VERSION ""

NS_ :

BS_:

BU_: _05_TCU _0B_GPS _0A_Precharge _00_CCU _01_MCU _02_Node_Pedal _03_Node_Front _04_HV_AMS _0B_Dash _06_LV_AMS _07_Shunt _08_Gyro _09_ASU _0C_VSU _0D_TSU_F _0E_TSU_R _0F_Node_Dflt Datalogger
VAL_TABLE_ VtAero_Range 3 "600-1100mBar" 2 "Differential" 1 "600-1200mBar" 0 "200-1200mBar" ;
VAL_TABLE_ VTable_ConfigIDs_CCU 15 "Voltage pump right" 14 "Voltage pump left" 13 "Laptrigger enabled (reboot)" 12 "Control eFuse Inverter right" 11 "Control eFuse Inverter left" 10 "Control eFuse Accumulator" 9 "Control eFuse CAN node" 8 "Torque pedal max way (mech lim)" 7 "Torque pedal full way (kickdown)" 6 "DRS mode" 5 "Fan Cooling manual speed" 4 "Fan Accu manual speed" 3 "Pump Inverter manual speed" 2 "Pump Motor manual speed" 1 "Cool mode" 0 "Reset Flash" ;
VAL_TABLE_ VTable_LV_AMS_I2C_State_Machine 4 "ShutdownPending" 3 "ManualRunning" 2 "ManualInit" 1 "Running" 0 "Init" ;
VAL_TABLE_ VTable_IMD_Status 2 "Undefined" 1 "Error" 0 "OK" ;
VAL_TABLE_ VTable_State_Bat 2 "State_Recalibrate" 1 "State_Load_Applied" 0 "State_Bat_Relaxed" ;
VAL_TABLE_ VTable_SOH_Estimator 3 "State_Reset" 2 "State_Running" 1 "State_Wait_For_Run" 0 "State_Init" ;
VAL_TABLE_ VTable_OCV_Estimator_State 3 "State_Reset" 2 "State_Running" 1 "State_Wait_For_Run" 0 "State_Init" ;
VAL_TABLE_ VTable_Bal_State 3 "State_Finished" 2 "State_Cool_Down" 1 "State_Active" 0 "State_Init" ;
VAL_TABLE_ DL_Status 8 "Error" 7 "Logging EM & FSD data" 5 "Logging FSD data" 3 "Logging EM data" 1 "DL idle, ready to log" ;

BO_ 3221225472 VECTOR__INDEPENDENT_SIG_MSG: 0 Vector__XXX
 SG_ New_Signal_471 : 0|8@1+ (1,0) [0|0] "" Vector__XXX
 SG_ New_Signal_470 : 0|8@1+ (1,0) [0|0] "" Vector__XXX
 SG_ Precharge_PM_Current_Too_High : 0|1@1+ (1,0) [0|1] "" Vector__XXX
 SG_ Current : 0|16@1- (0.05,0) [-1638.4|1638.35] "A" Vector__XXX
 SG_ Voltage : 0|16@1- (0.04,0) [-1310.72|1310.68] "V" Vector__XXX
 SG_ Power : 0|16@1- (3,0) [-98304|98301] "W" Vector__XXX
 SG_ Status : 0|8@1+ (1,0) [0|255] "" Vector__XXX
 SG_ MsgCntr : 0|8@1+ (1,0) [0|255] "" Vector__XXX
 SG_ NodeF_Force_FR : 0|16@0+ (0.02442,-28.8095) [0|100] "" Vector__XXX
 SG_ NodeR_Brake_Pressure : 0|16@0+ (0.03157,-12.9) [0|0] "Bar" Vector__XXX

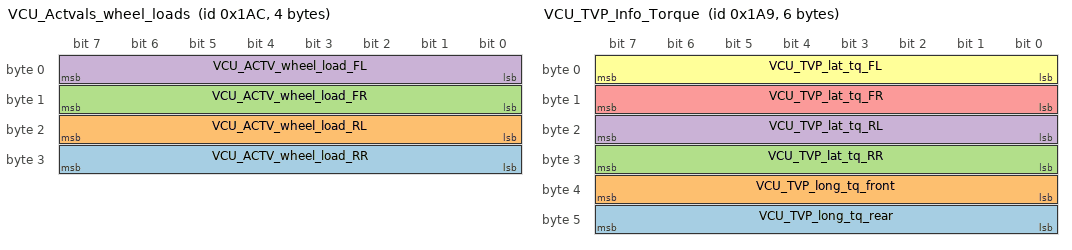
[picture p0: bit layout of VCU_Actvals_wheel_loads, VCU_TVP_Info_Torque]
BO_ 428 VCU_Actvals_wheel_loads: 4 Vector__XXX
 SG_ VCU_ACTV_wheel_load_RR : 24|8@1+ (10,0) [0|2550] "N" Vector__XXX
 SG_ VCU_ACTV_wheel_load_RL : 16|8@1+ (10,0) [0|2550] "N" Vector__XXX
 SG_ VCU_ACTV_wheel_load_FR : 8|8@1+ (10,0) [0|2550] "N" Vector__XXX
 SG_ VCU_ACTV_wheel_load_FL : 0|8@1+ (10,0) [0|2550] "N" Vector__XXX

BO_ 427 VCU_Actvals_steering: 6 Vector__XXX
 SG_ VCU_ACTV_wheel_angle_middle_deg : 32|16@1- (0.01,0) [-327.68|327.67] "deg" Vector__XXX
 SG_ VCU_ACTV_wheel_angle_FR : 16|16@1- (0.01,0) [-327.68|327.67] "deg" Vector__XXX
 SG_ VCU_ACTV_wheel_angle_FL : 0|16@1- (0.01,0) [-327.68|327.67] "deg" Vector__XXX

BO_ 425 VCU_TVP_Info_Torque: 6 Vector__XXX
 SG_ VCU_TVP_long_tq_rear : 40|8@1- (1,0) [-128|127] "%" Vector__XXX
 SG_ VCU_TVP_long_tq_front : 32|8@1- (1,0) [-128|127] "%" Vector__XXX
 SG_ VCU_TVP_lat_tq_RR : 24|8@1- (1,0) [-128|127] "%" Vector__XXX
 SG_ VCU_TVP_lat_tq_RL : 16|8@1- (1,0) [-128|127] "%" Vector__XXX
 SG_ VCU_TVP_lat_tq_FR : 8|8@1- (1,0) [-128|127] "%" Vector__XXX
 SG_ VCU_TVP_lat_tq_FL : 0|8@1- (1,0) [-128|127] "%" Vector__XXX

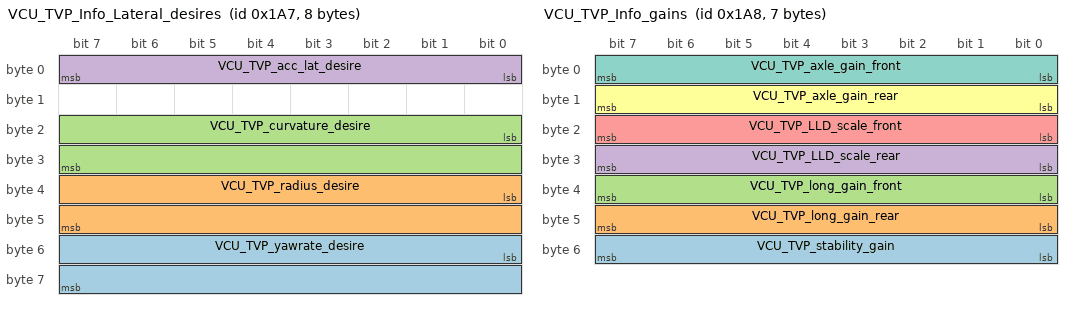
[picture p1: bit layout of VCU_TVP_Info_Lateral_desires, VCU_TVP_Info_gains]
BO_ 423 VCU_TVP_Info_Lateral_desires: 8 Vector__XXX
 SG_ VCU_TVP_yawrate_desire : 48|16@1- (0.001,0) [-32.768|32.767] "rad/s" Vector__XXX
 SG_ VCU_TVP_radius_desire : 32|16@1+ (0.1,0) [0|6553.5] "m" Vector__XXX
 SG_ VCU_TVP_curvature_desire : 16|16@1- (0.0001,0) [-3.2768|3.2767] "1/m" Vector__XXX
 SG_ VCU_TVP_acc_lat_desire : 0|8@1+ (0.1,0) [0|25.5] "m/s/s" Vector__XXX

BO_ 424 VCU_TVP_Info_gains: 7 Vector__XXX
 SG_ VCU_TVP_stability_gain : 48|8@1- (1,0) [-128|127] "%" Vector__XXX
 SG_ VCU_TVP_long_gain_rear : 40|8@1+ (1,0) [0|255] "%" Vector__XXX
 SG_ VCU_TVP_long_gain_front : 32|8@1+ (1,0) [0|255] "%" Vector__XXX
 SG_ VCU_TVP_LLD_scale_rear : 24|8@1+ (1,0) [0|255] "%" Vector__XXX
 SG_ VCU_TVP_LLD_scale_front : 16|8@1+ (1,0) [0|255] "%" Vector__XXX
 SG_ VCU_TVP_axle_gain_rear : 8|8@1- (1,0) [-128|127] "%" Vector__XXX
 SG_ VCU_TVP_axle_gain_front : 0|8@1- (1,0) [-128|127] "%" Vector__XXX

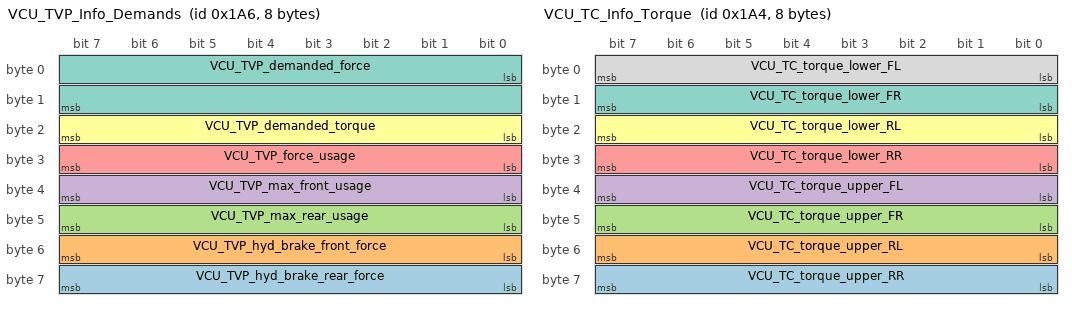
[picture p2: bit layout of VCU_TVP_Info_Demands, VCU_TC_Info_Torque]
BO_ 422 VCU_TVP_Info_Demands: 8 Vector__XXX
 SG_ VCU_TVP_hyd_brake_rear_force : 56|8@1+ (-10,0) [-2550|0] "N" Vector__XXX
 SG_ VCU_TVP_hyd_brake_front_force : 48|8@1+ (-10,0) [-2550|0] "N" Vector__XXX
 SG_ VCU_TVP_max_rear_usage : 40|8@1+ (1,0) [0|255] "%" Vector__XXX
 SG_ VCU_TVP_max_front_usage : 32|8@1+ (1,0) [0|255] "%" Vector__XXX
 SG_ VCU_TVP_force_usage : 24|8@1- (1,0) [-128|127] "%" Vector__XXX
 SG_ VCU_TVP_demanded_torque : 16|8@1- (1,0) [-128|127] "%" Vector__XXX
 SG_ VCU_TVP_demanded_force : 0|16@1- (1,0) [-32768|32767] "N" Vector__XXX

BO_ 421 VCU_TC_Info_Speed: 8 Vector__XXX
 SG_ VCU_TC_upper_speed_RR : 48|16@1+ (0.1,0) [0|6553.5] "rad/s" Vector__XXX
 SG_ VCU_TC_upper_speed_RL : 32|16@1+ (0.1,0) [0|6553.5] "rad/s" Vector__XXX
 SG_ VCU_TC_upper_speed_FR : 16|16@1+ (0.1,0) [0|6553.5] "rad/s" Vector__XXX
 SG_ VCU_TC_upper_speed_FL : 0|16@1+ (0.1,0) [0|6553.5] "rad/s" Vector__XXX

BO_ 420 VCU_TC_Info_Torque: 8 Vector__XXX
 SG_ VCU_TC_torque_upper_RR : 56|8@1- (1,0) [-128|127] "%" Vector__XXX
 SG_ VCU_TC_torque_upper_RL : 48|8@1- (1,0) [-128|127] "%" Vector__XXX
 SG_ VCU_TC_torque_upper_FR : 40|8@1- (1,0) [-128|127] "%" Vector__XXX
 SG_ VCU_TC_torque_upper_FL : 32|8@1- (1,0) [-128|127] "%" Vector__XXX
 SG_ VCU_TC_torque_lower_RR : 24|8@1- (1,0) [-128|127] "%" Vector__XXX
 SG_ VCU_TC_torque_lower_RL : 16|8@1- (1,0) [-128|127] "%" Vector__XXX
 SG_ VCU_TC_torque_lower_FR : 8|8@1- (1,0) [-128|127] "%" Vector__XXX
 SG_ VCU_TC_torque_lower_FL : 0|8@1- (1,0) [-128|127] "%" Vector__XXX

BO_ 419 VCU_PL_Limits: 2 Vector__XXX
 SG_ VCU_PL_Tq_max_lim : 8|8@1+ (1,0) [0|255] "%" Vector__XXX
 SG_ VCU_PL_Tq_min_lim : 0|8@1+ (-1,0) [-255|0] "%" Vector__XXX

BO_ 417 VCU_CFG_SETPOINTS_2: 8 Vector__XXX

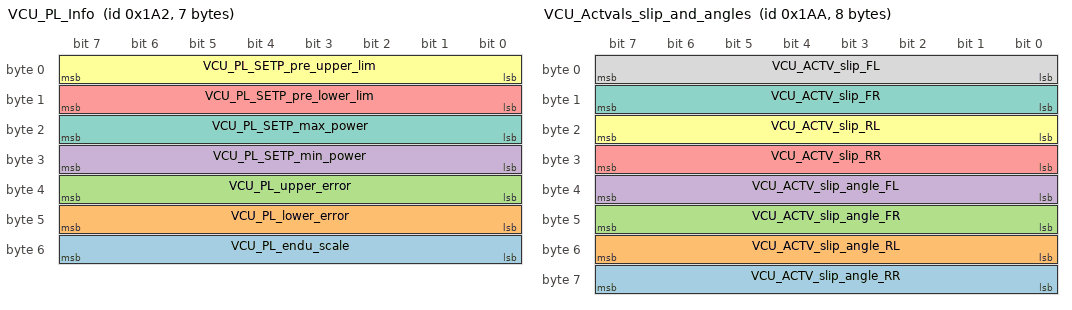
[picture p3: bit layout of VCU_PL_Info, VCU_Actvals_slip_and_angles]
BO_ 418 VCU_PL_Info: 7 Vector__XXX
 SG_ VCU_PL_endu_scale : 48|8@1+ (0.01,0) [0|2.55] "" Vector__XXX
 SG_ VCU_PL_lower_error : 40|8@1- (0.01,0) [-1.28|1.27] "" Vector__XXX
 SG_ VCU_PL_upper_error : 32|8@1- (0.01,0) [-1.28|1.27] "" Vector__XXX
 SG_ VCU_PL_SETP_min_power : 24|8@1- (1,0) [-128|127] "kW" Vector__XXX
 SG_ VCU_PL_SETP_pre_lower_lim : 8|8@1+ (-0.01,0) [-2.55|0] "" Vector__XXX
 SG_ VCU_PL_SETP_pre_upper_lim : 0|8@1- (0.01,0) [0|2.55] "" Vector__XXX
 SG_ VCU_PL_SETP_max_power : 16|8@1- (1,0) [-128|127] "kW" Vector__XXX

BO_ 426 VCU_Actvals_slip_and_angles: 8 Vector__XXX
 SG_ VCU_ACTV_slip_angle_RR : 56|8@1- (0.2,0) [-25.6|25.4] "deg" Vector__XXX
 SG_ VCU_ACTV_slip_angle_RL : 48|8@1- (0.2,0) [-25.6|25.4] "deg" Vector__XXX
 SG_ VCU_ACTV_slip_angle_FR : 40|8@1- (0.2,0) [-25.6|25.4] "deg" Vector__XXX
 SG_ VCU_ACTV_slip_angle_FL : 32|8@1- (0.2,0) [-25.6|25.4] "deg" Vector__XXX
 SG_ VCU_ACTV_slip_RR : 24|8@1- (1,0) [-128|127] "%" Vector__XXX
 SG_ VCU_ACTV_slip_RL : 16|8@1- (1,0) [-128|127] "%" Vector__XXX
 SG_ VCU_ACTV_slip_FR : 8|8@1- (1,0) [-128|127] "%" Vector__XXX
 SG_ VCU_ACTV_slip_FL : 0|8@1- (1,0) [-128|127] "%" Vector__XXX

BO_ 277 VCU_ACTVALS_1: 3 Vector__XXX
 SG_ VCU_ACTV_DRIVER_PEDALS : 16|8@1- (1,0) [-128|127] "%" Vector__XXX
 SG_ VCU_ACT_TS_POWER : 0|16@1- (0.01,0) [-327.68|327.67] "kW" Vector__XXX

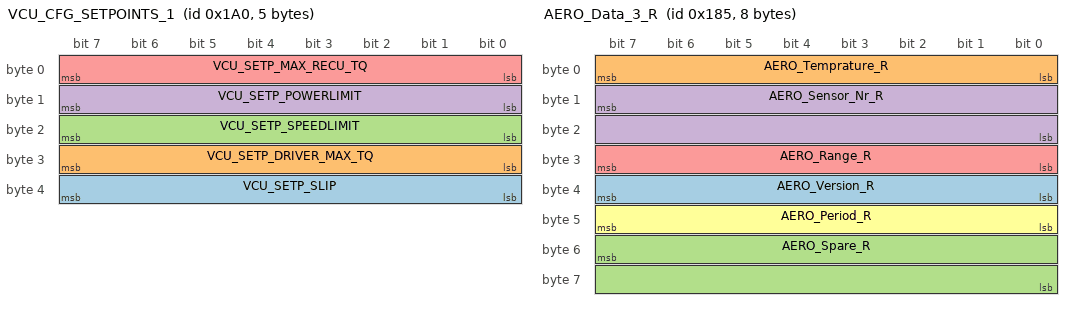
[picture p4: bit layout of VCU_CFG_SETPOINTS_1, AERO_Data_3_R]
BO_ 416 VCU_CFG_SETPOINTS_1: 5 Vector__XXX
 SG_ VCU_SETP_SLIP : 32|8@1+ (1,0) [0|255] "%" Vector__XXX
 SG_ VCU_SETP_DRIVER_MAX_TQ : 24|8@1+ (1,0) [0|100] "%" Vector__XXX
 SG_ VCU_SETP_SPEEDLIMIT : 16|8@1+ (1,0) [0|255] "km/h" Vector__XXX
 SG_ VCU_SETP_POWERLIMIT : 8|8@1+ (1,0) [0|255] "kW" Vector__XXX
 SG_ VCU_SETP_MAX_RECU_TQ : 0|8@1+ (0.1,0) [0|25.5] "Nm" Vector__XXX

BO_ 1008 TSU_N_FR: 8 _0D_TSU_F
 SG_ TSU_NT_C6 : 55|16@0+ (0.1,0) [-20|200] "°C" Vector__XXX
 SG_ TSU_NT_C5 : 39|16@0+ (0.1,0) [-20|200] "°C" Vector__XXX
 SG_ TSU_NT_C4 : 23|16@0+ (0.1,0) [-20|200] "°C" Vector__XXX
 SG_ TSU_NT_C3 : 7|16@0+ (0.1,0) [-20|200] "°C" Vector__XXX

BO_ 392 NodeF_SensorData_2: 8 Vector__XXX
 SG_ NodeF_Spring_Heave : 7|16@0+ (0.024652,-15.6787) [0|100] "mm" Vector__XXX
 SG_ NodeF_Force_FL : 23|16@0+ (0.02442,-28.8095) [0|100] "" Vector__XXX

BO_ 391 NodeR_Force: 4 Vector__XXX
 SG_ NodeR_Force_FR : 23|16@0+ (0.02442,-28.8095) [0|100] "" Vector__XXX
 SG_ NodeR_Force_FL : 7|16@0+ (0.02442,-28.8095) [0|100] "" Vector__XXX

BO_ 390 NodeR_SensorData: 8 Vector__XXX
 SG_ NodeR_Spring_Heave : 39|16@0+ (0.030758,-67.6368) [0|100] "mm" Vector__XXX
 SG_ NodeR_Spring_RL : 7|16@0+ (0.018423,-28.3641) [0|100] "mm" Vector__XXX
 SG_ NodeR_Spring_RR : 23|16@0+ (0.018464,-30.4627) [0|100] "mm" Vector__XXX

BO_ 389 AERO_Data_3_R: 8 Vector__XXX
 SG_ AERO_Version_R : 39|8@0+ (1,0) [0|0] "" Vector__XXX
 SG_ AERO_Temprature_R : 7|8@0- (1,0) [-10|100] "C" Vector__XXX
 SG_ AERO_Spare_R : 55|16@0+ (1,0) [0|0] "" Vector__XXX
 SG_ AERO_Sensor_Nr_R : 15|16@0+ (1,0) [0|0] "" Vector__XXX
 SG_ AERO_Range_R : 31|8@0+ (1,0) [0|0] "" Vector__XXX
 SG_ AERO_Period_R : 47|8@0+ (1,0) [0|0] "ms" Vector__XXX

BO_ 388 AERO_Data_2_R: 8 Vector__XXX
 SG_ AERO_Pressure8_R : 55|16@0+ (0.01,600) [600|1200] "mBar" Vector__XXX
 SG_ AERO_Pressure7_R : 39|16@0+ (0.01,600) [600|1200] "mBar" Vector__XXX
 SG_ AERO_Pressure6_R : 23|16@0+ (0.01,600) [600|1200] "mBar" Vector__XXX
 SG_ AERO_Pressure5_R : 7|16@0+ (0.01,600) [600|1200] "mBar" Vector__XXX

BO_ 387 AERO_Data_1_R: 8 Vector__XXX
 SG_ AERO_Pressure4_R : 55|16@0+ (0.01,600) [600|1200] "mBar" Vector__XXX
 SG_ AERO_Pressure3_R : 39|16@0+ (0.01,600) [600|1200] "mBar" Vector__XXX
 SG_ AERO_Pressure2_R : 23|16@0+ (0.01,600) [600|1200] "mBar" Vector__XXX
 SG_ AERO_Pressure1_R : 7|16@0+ (0.01,600) [600|1200] "mBar" Vector__XXX

BO_ 2035 AERO_Config_3: 8 Vector__XXX
 SG_ AERO_Opcode_3 : 7|8@0+ (1,0) [0|0] "" Vector__XXX
 SG_ AERO_MultiConfig_3 : 23|48@0+ (1,0) [0|0] "" Vector__XXX
 SG_ AERO_Message_Type_3 : 15|8@0+ (1,0) [0|0] "" Vector__XXX

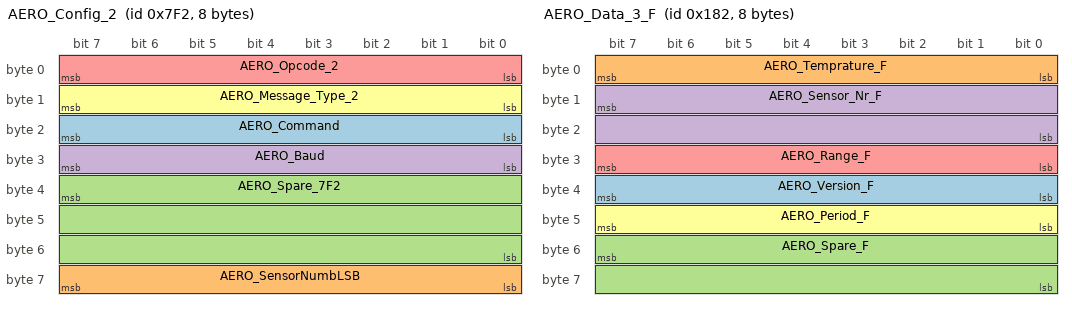
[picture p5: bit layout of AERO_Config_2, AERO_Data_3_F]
BO_ 2034 AERO_Config_2: 8 Vector__XXX
 SG_ AERO_Command : 23|8@0+ (1,0) [0|0] "" Vector__XXX
 SG_ AERO_SensorNumbLSB : 56|8@1- (1,0) [0|0] "" Vector__XXX
 SG_ AERO_Spare_7F2 : 39|24@0+ (1,0) [0|0] "" Vector__XXX
 SG_ AERO_Baud : 31|8@0+ (1,0) [0|0] "" Vector__XXX
 SG_ AERO_Opcode_2 : 7|8@0+ (1,0) [0|0] "" Vector__XXX
 SG_ AERO_Message_Type_2 : 15|8@0+ (1,0) [0|0] "" Vector__XXX

BO_ 2033 AERO_Config_1: 8 Vector__XXX
 SG_ AERO_MultiConfig_1 : 23|48@0+ (1,0) [0|0] "" Vector__XXX
 SG_ AERO_Message_Type_1 : 15|8@0+ (1,0) [0|0] "" Vector__XXX
 SG_ AERO_Opcode_1 : 7|8@0+ (1,0) [0|0] "" Vector__XXX

BO_ 386 AERO_Data_3_F: 8 Vector__XXX
 SG_ AERO_Version_F : 39|8@0+ (1,0) [0|0] "" Vector__XXX
 SG_ AERO_Temprature_F : 7|8@0- (1,0) [-10|100] "C" Vector__XXX
 SG_ AERO_Spare_F : 55|16@0+ (1,0) [0|0] "" Vector__XXX
 SG_ AERO_Sensor_Nr_F : 15|16@0+ (1,0) [0|0] "" Vector__XXX
 SG_ AERO_Range_F : 31|8@0+ (1,0) [0|0] "" Vector__XXX
 SG_ AERO_Period_F : 47|8@0+ (1,0) [0|0] "ms" Vector__XXX

BO_ 385 AERO_Data_2_F: 8 Vector__XXX
 SG_ AERO_Pressure8_F : 55|16@0+ (0.01,600) [600|1200] "mBar" Vector__XXX
 SG_ AERO_Pressure7_F : 39|16@0+ (0.01,600) [600|1200] "mBar" Vector__XXX
 SG_ AERO_Pressure6_F : 23|16@0+ (0.01,600) [600|1200] "mBar" Vector__XXX
 SG_ AERO_Pressure5_F : 7|16@0+ (0.01,600) [600|1200] "mBar" Vector__XXX

BO_ 384 AERO_Data_1_F: 8 Vector__XXX
 SG_ AERO_Pressure4_F : 55|16@0+ (0.01,600) [600|1200] "mBar" Vector__XXX
 SG_ AERO_Pressure3_F : 39|16@0+ (0.01,600) [600|1200] "mBar" Vector__XXX
 SG_ AERO_Pressure2_F : 23|16@0+ (0.01,600) [600|1200] "mBar" Vector__XXX
 SG_ AERO_Pressure1_F : 7|16@0+ (0.01,600) [600|1200] "mBar" Vector__XXX

BO_ 1973 Config_Tel_Write_Dash: 4 _05_TCU
 SG_ Dash_Config_Value_W : 23|16@0+ (1,0) [0|0] "" Vector__XXX
 SG_ Dash_Config_ID_W : 7|16@0+ (1,0) [0|0] "" Vector__XXX

BO_ 1717 Config_Tel_Read_Dash: 4 _05_TCU
 SG_ Dash_Config_Value_RD : 23|16@0+ (1,0) [0|0] "" Vector__XXX
 SG_ Dash_Config_ID_RD : 7|16@0+ (1,0) [0|0] "" Vector__XXX

BO_ 1627 Config_Tel_Response_Dash: 4 _0B_Dash
 SG_ Dash_Config_Value_RX : 23|16@0+ (1,0) [0|0] "" Vector__XXX
 SG_ Dash_Config_ID_RX : 7|16@0+ (1,0) [0|0] "" Vector__XXX

BO_ 773 TCU_Monitoring: 2 _05_TCU
 SG_ TCU_Current_consumption : 7|16@0+ (0.00013573,0) [0|0.56] "A" Vector__XXX

BO_ 292 AMS_Capacity_And_OCV: 4 Vector__XXX
 SG_ AMS_OCV : 23|16@0- (1,0) [2700|4200] "mV" Vector__XXX
 SG_ AMS_Capacity : 7|16@0- (0.001,0) [0|0] "Ah" Vector__XXX

BO_ 976 CCU_LV_Currents_3_RS17: 2 _00_CCU
 SG_ CCU_Current_LV_Fans_Cooling_RS17 : 7|16@0+ (0.006104432,0) [0|25] "A" Vector__XXX

BO_ 529 MCU_Act_Vals_3: 3 _01_MCU
 SG_ MCU_ActVal_Speed_Filtered : 15|16@0- (0.1,0) [0|0] "m/s" Vector__XXX
 SG_ MCU_ActVal_Max_Recup_Curr_Setp : 7|8@0+ (1,0) [0|255] "A" Vector__XXX

BO_ 1021 GPS_Status: 8 _0B_GPS
 SG_ MsgAnzahl m1 : 56|8@1+ (1,0) [0|12] "" Vector__XXX
 SG_ MsgNummer m1 : 48|8@1+ (1,0) [0|12] "" Vector__XXX
 SG_ SNR m1 : 40|8@1+ (1,0) [0|99] "dBhz" Vector__XXX
 SG_ Erhebungswinkel m1 : 32|8@1- (1,0) [-9|90] "Grad" Vector__XXX
 SG_ Azimut m1 : 16|16@1+ (1,0) [0|359] "Grad" Vector__XXX
 SG_ Sat_ID m1 : 8|8@1+ (1,0) [1|32] "" Vector__XXX
 SG_ Sat_aktiv m1 : 0|4@1+ (1,0) [0|1] "" Vector__XXX
 SG_ VDOP m0 : 48|16@1+ (0.1,0) [0|99.9] "m" Vector__XXX
 SG_ HDOP m0 : 32|16@1+ (0.1,0) [0|99.9] "m" Vector__XXX
 SG_ PDOP m0 : 16|16@1+ (0.1,0) [0|99.9] "m" Vector__XXX
 SG_ AnzSichtbSat m0 : 8|8@1+ (1,0) [0|12] "" Vector__XXX
 SG_ AnzAktSat m0 : 0|4@1+ (1,0) [0|12] "" Vector__XXX
 SG_ Typ M : 4|4@1+ (1,0) [0|1] "" Vector__XXX

BO_ 1020 GPS_Speed: 4 _0B_GPS
 SG_ GPS_course : 16|16@1+ (0.1,0) [0|359.9] "Grad" Vector__XXX
 SG_ GPS_speed : 0|16@1+ (0.1,0) [0|999.9] "km/h" Vector__XXX

BO_ 1019 GPS_Location: 8 _0B_GPS
 SG_ GPS_x : 32|32@1- (2.7777777778E-006,0) [-180|180] "Grad" Vector__XXX
 SG_ GPS_y : 0|32@1- (2.7777777778E-006,0) [-90|90] "Grad" Vector__XXX

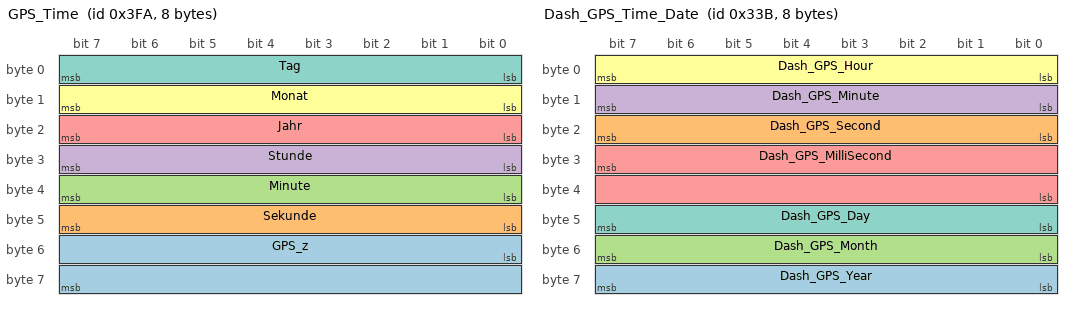
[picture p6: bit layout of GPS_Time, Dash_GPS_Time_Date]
BO_ 1018 GPS_Time: 8 _0B_GPS
 SG_ GPS_z : 48|16@1- (1,0) [-9999|32767] "m" Vector__XXX
 SG_ Sekunde : 40|8@1+ (1,0) [0|59] "Sekunden" Vector__XXX
 SG_ Minute : 32|8@1+ (1,0) [0|59] "Minuten" Vector__XXX
 SG_ Stunde : 24|8@1+ (1,0) [0|23] "Stunden" Vector__XXX
 SG_ Jahr : 16|8@1+ (1,0) [0|99] "Jahr" Vector__XXX
 SG_ Monat : 8|8@1+ (1,0) [1|12] "Monat" Vector__XXX
 SG_ Tag : 0|8@1+ (1,0) [1|31] "Tag" Vector__XXX

BO_ 282 Precharge_Monitoring: 8 _0A_Precharge
 SG_ Precharge_PreRel_closed : 31|1@1+ (1,0) [0|0] "" Vector__XXX
 SG_ Precharge_AIR2_closed : 30|1@1+ (1,0) [0|0] "" Vector__XXX
 SG_ Precharge_AIR1_closed : 29|1@1+ (1,0) [0|0] "" Vector__XXX
 SG_ Precharge_Time_Min : 39|16@0+ (1,0) [0|0] "ms" Vector__XXX
 SG_ Precharge_Time_Max : 55|16@0+ (1,0) [0|0] "ms" Vector__XXX
 SG_ Precharge_uC_Reset : 27|1@1+ (1,0) [0|1] "" Vector__XXX
 SG_ Precharge_uC_OK : 28|1@1+ (1,0) [0|1] "" Vector__XXX
 SG_ Precharge_Current : 7|16@0- (1,0) [-32768|32767] "A" Vector__XXX
 SG_ Precharge_PM_Pre_Sig : 18|1@1+ (1,0) [0|1] "" Vector__XXX
 SG_ Precharge_PM_Pre_Run_Min_Latch : 25|1@1+ (1,0) [0|1] "" Vector__XXX
 SG_ Precharge_PM_Pre_Run : 24|1@1+ (1,0) [0|1] "" Vector__XXX
 SG_ Precharge_PM_Pre_Reset_Inv : 22|1@1+ (1,0) [0|1] "" Vector__XXX
 SG_ Precharge_PM_Pre_Less_40V : 26|1@1+ (1,0) [0|1] "" Vector__XXX
 SG_ Precharge_PM_Pre_AUX : 21|1@1+ (1,0) [0|1] "" Vector__XXX
 SG_ Precharge_PM_AIR2_Sig : 17|1@1+ (1,0) [0|1] "" Vector__XXX
 SG_ Precharge_PM_AIR2_AUX : 20|1@1+ (1,0) [0|1] "" Vector__XXX
 SG_ Precharge_PM_AIR1_Sig : 16|1@1+ (1,0) [0|1] "" Vector__XXX
 SG_ Precharge_PM_AIR1_AUX : 19|1@1+ (1,0) [0|1] "" Vector__XXX
 SG_ Precharge_PM_5V_SC : 23|1@1+ (1,0) [0|1] "" Vector__XXX

BO_ 944 CCU_Cooling_Temps: 8 _00_CCU
 SG_ CCU_Temp_MotR_Out_MotF_In : 55|16@0+ (0.0225,-10) [0|0] "deg" Vector__XXX
 SG_ CCU_Temp_Inv_Out_Mot_In : 39|16@0+ (0.0225,-10) [0|0] "deg" Vector__XXX
 SG_ CCU_Temp_MotF_Out_HE_In : 23|16@0+ (0.0225,-10) [0|0] "deg" Vector__XXX
 SG_ CCU_Temp_HE_Out_Inv_In : 7|16@0+ (0.0225,-10) [0|0] "deg" Vector__XXX

BO_ 843 Dash_GPS_Status: 4 _0B_Dash
 SG_ Dash_GPS_Velocity : 23|16@0+ (1,0) [0|0] "" Vector__XXX
 SG_ Dash_GPS_Signal_Integrity : 15|8@0+ (1,0) [0|0] "" Vector__XXX
 SG_ Dash_GPS_Satelite : 7|8@0+ (1,0) [0|0] "" Vector__XXX

BO_ 827 Dash_GPS_Time_Date: 8 _0B_Dash
 SG_ Dash_GPS_Year : 63|8@0+ (1,0) [0|0] "" Vector__XXX
 SG_ Dash_GPS_Second : 23|8@0+ (1,0) [0|0] "" Vector__XXX
 SG_ Dash_GPS_Month : 55|8@0+ (1,0) [0|0] "" Vector__XXX
 SG_ Dash_GPS_Minute : 15|8@0+ (1,0) [0|0] "" Vector__XXX
 SG_ Dash_GPS_MilliSecond : 31|16@0+ (1,0) [0|0] "" Vector__XXX
 SG_ Dash_GPS_Hour : 7|8@0+ (1,0) [0|0] "" Vector__XXX
 SG_ Dash_GPS_Day : 47|8@0+ (1,0) [0|0] "" Vector__XXX

BO_ 811 Dash_GPS_Long_Lat: 8 _0B_Dash
 SG_ Dash_GPS_Longitude : 39|32@0+ (1,0) [0|0] "" Vector__XXX
 SG_ Dash_GPS_Latitude : 7|32@0+ (1,0) [0|0] "" Vector__XXX

BO_ 795 Dash_Lap_Time: 3 _0B_Dash
 SG_ Dash_Lap_Time : 7|24@0+ (0.001,0) [0|0] "" Vector__XXX

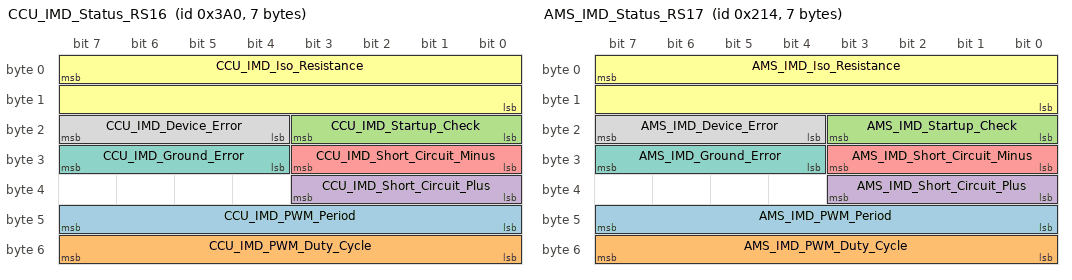
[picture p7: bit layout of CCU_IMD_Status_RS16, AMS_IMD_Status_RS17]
BO_ 928 CCU_IMD_Status_RS16: 7 _00_CCU
 SG_ CCU_IMD_PWM_Period : 47|8@0+ (1,0) [0|0] "Hz" Vector__XXX
 SG_ CCU_IMD_PWM_Duty_Cycle : 55|8@0+ (1,0) [0|0] "%" Vector__XXX
 SG_ CCU_IMD_Startup_Check : 16|4@1+ (1,0) [0|0] "" Vector__XXX
 SG_ CCU_IMD_Short_Circuit_Plus : 32|4@1+ (1,0) [0|0] "" Vector__XXX
 SG_ CCU_IMD_Short_Circuit_Minus : 24|4@1+ (1,0) [0|0] "" Vector__XXX
 SG_ CCU_IMD_Iso_Resistance : 7|16@0+ (0.001,0) [0|6] "MOhm" Vector__XXX
 SG_ CCU_IMD_Ground_Error : 28|4@1+ (1,0) [0|0] "" Vector__XXX
 SG_ CCU_IMD_Device_Error : 20|4@1+ (1,0) [0|0] "" Vector__XXX

BO_ 1110 LV_AMS_Internal_States: 2 _06_LV_AMS
 SG_ LV_AMS_Number_Of_Cells : 15|8@0+ (1,0) [3|8] "" Vector__XXX
 SG_ LV_AMS_I2C_State_Machine : 7|8@0+ (1,0) [0|0] "" Vector__XXX

BO_ 550 LV_AMS_Temps: 8 _06_LV_AMS
 SG_ LV_AMS_Temp_Internal : 55|16@0+ (0.1,0) [0|60] "C" Vector__XXX
 SG_ LV_AMS_Cell_Temp_Min : 39|16@0- (0.1,0) [0|60] "C" Vector__XXX
 SG_ LV_AMS_Cell_Temp_Max : 7|16@0- (0.1,0) [0|60] "C" Vector__XXX
 SG_ LV_AMS_Cell_Temp_Avg : 23|16@0- (0.1,0) [0|60] "C" Vector__XXX

BO_ 532 AMS_IMD_Status_RS17: 7 _04_HV_AMS
 SG_ AMS_IMD_PWM_Period : 47|8@0+ (1,0) [0|0] "Hz" Vector__XXX
 SG_ AMS_IMD_PWM_Duty_Cycle : 55|8@0+ (1,0) [0|0] "%" Vector__XXX
 SG_ AMS_IMD_Startup_Check : 16|4@1+ (1,0) [0|0] "" Vector__XXX
 SG_ AMS_IMD_Short_Circuit_Plus : 32|4@1+ (1,0) [0|0] "" Vector__XXX
 SG_ AMS_IMD_Short_Circuit_Minus : 24|4@1+ (1,0) [0|0] "" Vector__XXX
 SG_ AMS_IMD_Iso_Resistance : 7|16@0+ (0.001,0) [0|6] "MOhm" Vector__XXX
 SG_ AMS_IMD_Ground_Error : 28|4@1+ (1,0) [0|0] "" Vector__XXX
 SG_ AMS_IMD_Device_Error : 20|4@1+ (1,0) [0|0] "" Vector__XXX

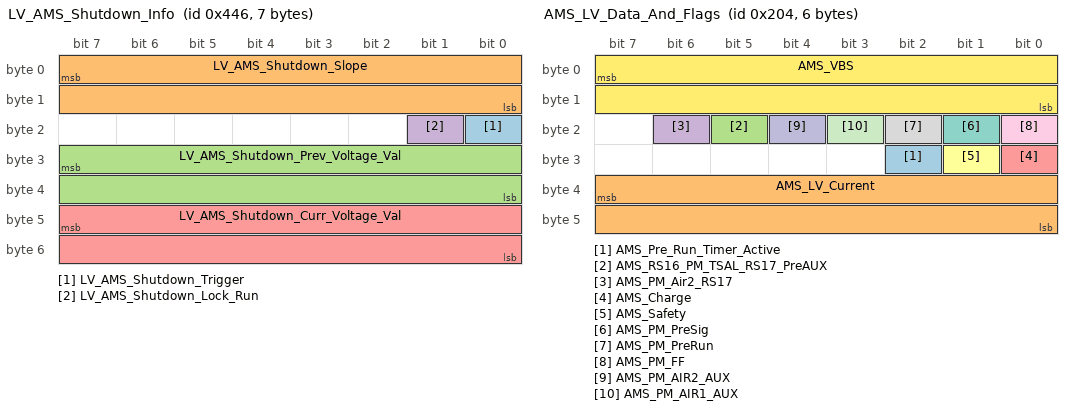
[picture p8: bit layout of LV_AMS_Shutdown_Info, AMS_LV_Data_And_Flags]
BO_ 1094 LV_AMS_Shutdown_Info: 7 _06_LV_AMS
 SG_ LV_AMS_Shutdown_Trigger : 16|1@0+ (1,0) [0|0] "" Vector__XXX
 SG_ LV_AMS_Shutdown_Slope : 7|16@0- (1,0) [0|0] "" Vector__XXX
 SG_ LV_AMS_Shutdown_Prev_Voltage_Val : 31|16@0+ (1,0) [0|0] "" Vector__XXX
 SG_ LV_AMS_Shutdown_Lock_Run : 17|1@0+ (1,0) [0|0] "" Vector__XXX
 SG_ LV_AMS_Shutdown_Curr_Voltage_Val : 47|16@0+ (1,0) [0|0] "" Vector__XXX

BO_ 1078 LV_AMS_Diagnostic_Data_3: 8 _06_LV_AMS
 SG_ LV_AMS_Temp_Cell_6 : 55|16@0+ (0.1,0) [0|60] "C" Vector__XXX
 SG_ LV_AMS_Temp_Cell_5 : 39|16@0+ (0.1,0) [0|60] "C" Vector__XXX
 SG_ LV_AMS_Temp_Cell_4 : 23|16@0+ (0.1,0) [0|60] "C" Vector__XXX
 SG_ LV_AMS_Temp_Cell_3 : 7|16@0+ (0.1,0) [0|60] "C" Vector__XXX

BO_ 779 Dash_Monitoring: 2 _0B_Dash
 SG_ Dash_Current_consumption : 7|16@0+ (0.00013573,0) [0|0.56] "A" Vector__XXX

BO_ 912 CCU_LV_Currents_2_RS17: 8 _00_CCU
 SG_ CCU_Current_LV_Inverter_R_RS17 : 55|16@0+ (0.001150741,0) [0|5] "A" Vector__XXX
 SG_ CCU_Current_LV_Inverter_L_RS17 : 39|16@0+ (0.001150741,0) [0|5] "A" Vector__XXX
 SG_ CCU_Current_LV_Optical_Sens_RS17 : 23|16@0+ (0.001150741,0) [0|5] "A" Vector__XXX
 SG_ CCU_Current_LV_Accu_RS17 : 7|16@0+ (0.001150741,0) [0|5] "A" Vector__XXX

BO_ 896 CCU_LV_Currents_1_RS17: 8 _00_CCU
 SG_ CCU_Current_LV_Fans_Accu_RS17 : 55|16@0+ (0.006104432,0) [0|25] "A" Vector__XXX
 SG_ CCU_Current_LV_Pumps_RS17 : 39|16@0+ (0.006104432,0) [0|25] "A" Vector__XXX
 SG_ CCU_Current_LV_CCU_RS17 : 23|16@0+ (0.000367258,0) [0|1.5] "A" Vector__XXX
 SG_ CCU_Current_LV_Total_RS17 : 7|16@0+ (0.006104432,0) [0|25] "A" Vector__XXX

BO_ 516 AMS_LV_Data_And_Flags: 6 _04_HV_AMS
 SG_ AMS_Pre_Run_Timer_Active : 26|1@1+ (1,0) [0|0] "" Vector__XXX
 SG_ AMS_LV_Current : 39|16@0+ (1,0) [0|0] "" Vector__XXX
 SG_ AMS_RS16_PM_TSAL_RS17_PreAUX : 21|1@0+ (1,0) [0|0] "" Vector__XXX
 SG_ AMS_PM_Air2_RS17 : 22|1@0+ (1,0) [0|0] "" Vector__XXX
 SG_ AMS_Charge : 24|1@0+ (1,0) [0|0] "" Vector__XXX
 SG_ AMS_Safety : 25|1@0+ (1,0) [0|0] "" Vector__XXX
 SG_ AMS_PM_PreSig : 17|1@0+ (1,0) [0|0] "" Vector__XXX
 SG_ AMS_PM_PreRun : 18|1@0+ (1,0) [0|0] "" Vector__XXX
 SG_ AMS_PM_FF : 16|1@0+ (1,0) [0|0] "" Vector__XXX
 SG_ AMS_PM_AIR2_AUX : 20|1@0+ (1,0) [0|0] "" Vector__XXX
 SG_ AMS_PM_AIR1_AUX : 19|1@0+ (1,0) [0|0] "" Vector__XXX
 SG_ AMS_VBS : 7|16@0+ (0.01055,0) [15|35] "V" Vector__XXX

BO_ 948 AMS_Fail_Counter_2: 3 _04_HV_AMS
 SG_ AMS_ISR_OOB_Failcounter : 23|8@0+ (1,0) [0|20] "" Vector__XXX
 SG_ AMS_Fail_Counter_COM_Recov : 15|8@0+ (1,0) [0|20] "" Vector__XXX
 SG_ AMS_Fail_Counter_Cell_Limit_Exc : 7|8@0+ (1,0) [0|0] "" Vector__XXX

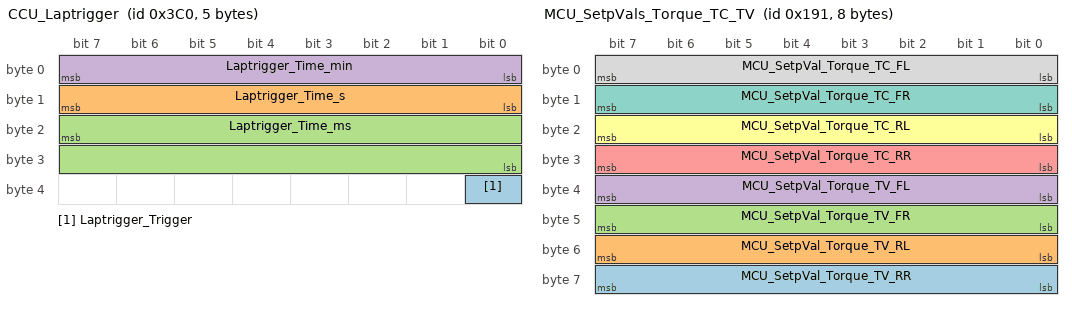
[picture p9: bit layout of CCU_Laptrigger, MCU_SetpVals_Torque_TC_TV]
BO_ 960 CCU_Laptrigger: 5 _00_CCU
 SG_ Laptrigger_Trigger : 32|1@0+ (1,0) [0|0] "" Vector__XXX
 SG_ Laptrigger_Time_s : 15|8@0+ (1,0) [0|0] "s" Vector__XXX
 SG_ Laptrigger_Time_ms : 23|16@0+ (1,0) [0|0] "ms" Vector__XXX
 SG_ Laptrigger_Time_min : 7|8@0+ (1,0) [0|0] "min" Vector__XXX

BO_ 835 NodeF_Monitoring: 2 _03_Node_Front
 SG_ NodeF_Current_Consumption : 7|16@0+ (1,0) [0|851] "mA" Vector__XXX

BO_ 834 NodeP_Monitoring: 2 _02_Node_Pedal
 SG_ NodeP_Current_Consumption : 7|16@0+ (1,0) [0|851] "mA" Vector__XXX

BO_ 819 Node_Testsigs: 8 Vector__XXX
 SG_ Node_Testsig_Unfiltered_2 : 55|16@0- (1,0) [0|0] "" Vector__XXX
 SG_ Node_Testsig_Unfiltered_1 : 23|16@0- (1,0) [0|0] "" Vector__XXX
 SG_ Node_Testsig_Filtered_2 : 39|16@0- (1,0) [0|0] "" Vector__XXX
 SG_ Node_Testsig_Filtered_1 : 7|16@0- (1,0) [0|0] "" Vector__XXX

BO_ 772 AMS_Cell_Nrs: 4 _04_HV_AMS
 SG_ AMS_Cell_Number_Voltage_Min : 31|8@0+ (1,0) [0|150] "" Vector__XXX
 SG_ AMS_Cell_Number_Voltage_Max : 23|8@0+ (1,0) [0|150] "" Vector__XXX
 SG_ AMS_Cell_Number_Temp_Min : 15|8@0+ (1,0) [0|50] "" Vector__XXX
 SG_ AMS_Cell_Number_Temp_Max : 7|8@0+ (1,0) [0|50] "" Vector__XXX

BO_ 401 MCU_SetpVals_Torque_TC_TV: 8 _01_MCU
 SG_ MCU_SetpVal_Torque_TV_RR : 63|8@0- (1,0) [-35|35] "Nm" Vector__XXX
 SG_ MCU_SetpVal_Torque_TV_RL : 55|8@0- (1,0) [-35|35] "Nm" Vector__XXX
 SG_ MCU_SetpVal_Torque_TV_FR : 47|8@0- (1,0) [-35|35] "Nm" Vector__XXX
 SG_ MCU_SetpVal_Torque_TV_FL : 39|8@0- (1,0) [-35|35] "Nm" Vector__XXX
 SG_ MCU_SetpVal_Torque_TC_RR : 31|8@0- (1,0) [-35|35] "Nm" Vector__XXX
 SG_ MCU_SetpVal_Torque_TC_RL : 23|8@0- (1,0) [-35|35] "Nm" Vector__XXX
 SG_ MCU_SetpVal_Torque_TC_FR : 15|8@0- (1,0) [-35|35] "Nm" Vector__XXX
 SG_ MCU_SetpVal_Torque_TC_FL : 7|8@0- (1,0) [-35|35] "Nm" Vector__XXX

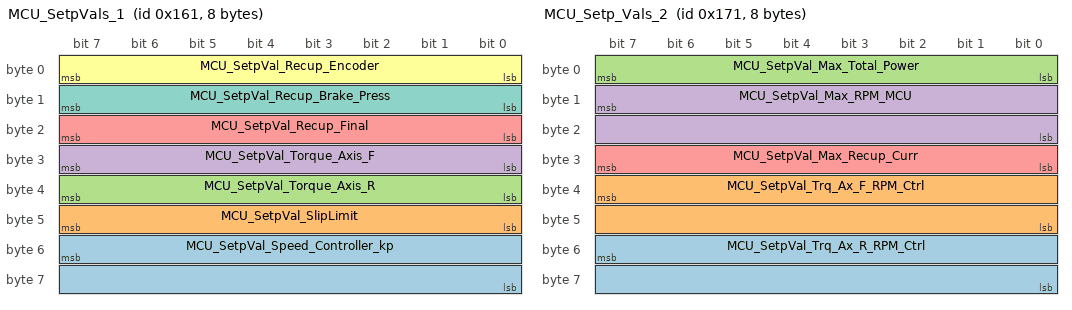
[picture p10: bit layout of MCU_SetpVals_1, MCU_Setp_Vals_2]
BO_ 353 MCU_SetpVals_1: 8 _01_MCU
 SG_ MCU_SetpVal_Speed_Controller_kp : 55|16@0+ (0.0001,0) [0|0] "" Vector__XXX
 SG_ MCU_SetpVal_SlipLimit : 47|8@0+ (1,0) [0|0] "" Vector__XXX
 SG_ MCU_SetpVal_Torque_Axis_R : 39|8@0- (1,0) [-115|115] "Nm" Vector__XXX
 SG_ MCU_SetpVal_Torque_Axis_F : 31|8@0- (1,0) [-115|115] "Nm" Vector__XXX
 SG_ MCU_SetpVal_Recup_Final : 23|8@0+ (1,0) [0|110] "%" Vector__XXX
 SG_ MCU_SetpVal_Recup_Encoder : 7|8@0+ (1,0) [0|110] "%" Vector__XXX
 SG_ MCU_SetpVal_Recup_Brake_Press : 15|8@0+ (1,0) [0|110] "%" Vector__XXX

BO_ 369 MCU_Setp_Vals_2: 8 _01_MCU
 SG_ MCU_SetpVal_Trq_Ax_R_RPM_Ctrl : 55|16@0- (0.1,0) [-115|115] "Nm" Vector__XXX
 SG_ MCU_SetpVal_Trq_Ax_F_RPM_Ctrl : 39|16@0- (0.1,0) [-115|115] "Nm" Vector__XXX
 SG_ MCU_SetpVal_Max_Total_Power : 7|8@0+ (1,0) [0|100] "kW" Vector__XXX
 SG_ MCU_SetpVal_Max_RPM_MCU : 15|16@0+ (1,0) [0|20000] "rpm" Vector__XXX
 SG_ MCU_SetpVal_Max_Recup_Curr : 31|8@0+ (1,0) [0|80] "A" Vector__XXX

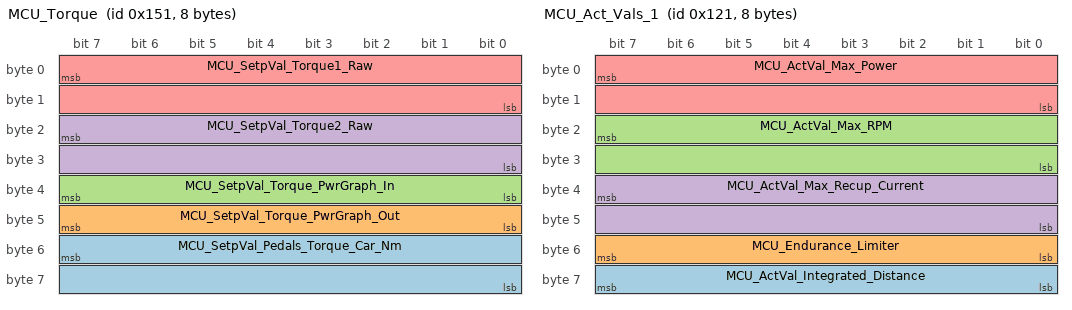
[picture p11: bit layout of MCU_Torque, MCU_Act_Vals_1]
BO_ 337 MCU_Torque: 8 _01_MCU
 SG_ MCU_SetpVal_Pedals_Torque_Car_Nm : 55|16@0- (0.1,0) [-115|115] "Nm" Vector__XXX
 SG_ MCU_SetpVal_Torque_PwrGraph_Out : 47|8@0+ (1,0) [0|110] "%" Vector__XXX
 SG_ MCU_SetpVal_Torque_PwrGraph_In : 39|8@0+ (1,0) [0|110] "%" Vector__XXX
 SG_ MCU_SetpVal_Torque2_Raw : 23|16@0+ (1,0) [0|4095] "" Vector__XXX
 SG_ MCU_SetpVal_Torque1_Raw : 7|16@0+ (1,0) [0|4095] "" Vector__XXX

BO_ 321 MCU_States_And_Flags: 3 _01_MCU
 SG_ MCU_StateActual_Temp_Rcp_Enabled : 19|1@0+ (1,0) [0|0] "" Vector__XXX
 SG_ MCU_StateActual_TV_Yaw_Ctrl : 22|1@0+ (1,0) [0|0] "" Vector__XXX
 SG_ MCU_StateActual_TV_Pre_Ctrl : 23|1@0+ (1,0) [0|0] "" Vector__XXX
 SG_ MCU_StateActual_TV_Open_Loop : 21|1@0+ (1,0) [0|0] "" Vector__XXX
 SG_ MCU_StateActual_TC_Enabled : 20|1@0+ (1,0) [0|0] "" Vector__XXX
 SG_ MCU_StateActual_Recup_Enabled : 18|1@0+ (1,0) [0|0] "" Vector__XXX
 SG_ MCU_StateActual_Eng_Brake : 17|1@0+ (1,0) [0|0] "" Vector__XXX
 SG_ MCU_StateActual_End_Limiter : 16|1@0+ (1,0) [0|0] "" Vector__XXX
 SG_ MCU_StateActual_Btn_End_Limiter : 6|1@1+ (1,0) [0|0] "" Vector__XXX
 SG_ MCU_StateActual_Btn_Recup : 7|1@1+ (1,0) [0|0] "" Vector__XXX
 SG_ MCU_StateConfig_TV_Yaw_Ctrl : 15|1@0+ (1,0) [0|0] "" Vector__XXX
 SG_ MCU_StateConfig_TV_Pre_Ctrl : 14|1@0+ (1,0) [0|0] "" Vector__XXX
 SG_ MCU_StateConfig_TV_Open_Loop : 13|1@0+ (1,0) [0|0] "" Vector__XXX
 SG_ MCU_StateConfig_TC_Enabled : 12|1@0+ (1,0) [0|0] "" Vector__XXX
 SG_ MCU_StateConfig_Recup_Enabled : 4|1@0+ (1,0) [0|0] "" Vector__XXX
 SG_ MCU_StateConfig_Eng_Brake : 5|1@0+ (1,0) [0|0] "" Vector__XXX
 SG_ MCU_StateConfig_End_Limiter : 3|1@0+ (1,0) [0|0] "" Vector__XXX
 SG_ MCU_StateActual_Btn_Driver_Reset : 2|1@0+ (1,0) [0|0] "" Vector__XXX
 SG_ MCU_StateActual_Slower_5kph_RR : 11|1@0+ (1,0) [0|0] "" Vector__XXX
 SG_ MCU_StateActual_Slower_5kph_RL : 10|1@0+ (1,0) [0|0] "" Vector__XXX
 SG_ MCU_StateActual_Slower_5kph_FR : 9|1@0+ (1,0) [0|0] "" Vector__XXX
 SG_ MCU_StateActual_Volt_Rcp_Enabled : 1|1@0+ (1,0) [0|0] "" Vector__XXX
 SG_ MCU_StateActual_Slower_5kph_FL : 8|1@0+ (1,0) [0|0] "" Vector__XXX
 SG_ MCU_StateActual_AIR2 : 0|1@0+ (1,0) [0|0] "" Vector__XXX

BO_ 305 MCU_Act_Vals_2: 8 _01_MCU
 SG_ MCU_Est_End_Capacity_Ah : 63|8@0+ (0.1,0) [0|14] "Ah" Vector__XXX
 SG_ MCU_Endurance_Completed_pct : 55|8@0+ (1,0) [0|100] "%" Vector__XXX
 SG_ MCU_ActVal_Avg_Velocity_Filtered : 39|16@0- (1,0) [0|2000] "rpm" Vector__XXX
 SG_ MCU_ActVal_Total_Distance : 7|32@0- (0.001,0) [0|500] "km" Vector__XXX

BO_ 289 MCU_Act_Vals_1: 8 _01_MCU
 SG_ MCU_ActVal_Integrated_Distance : 63|8@0+ (100,0) [0|0] "m" Vector__XXX
 SG_ MCU_Endurance_Limiter : 55|8@0+ (1,0) [0|100] "%" Vector__XXX
 SG_ MCU_ActVal_Max_RPM : 23|16@0- (1,0) [-10|20000] "rpm" Vector__XXX
 SG_ MCU_ActVal_Max_Recup_Current : 39|16@0- (0.1,0) [0|100] "A" Vector__XXX
 SG_ MCU_ActVal_Max_Power : 7|16@0- (0.01,0) [30|100] "kW" Vector__XXX

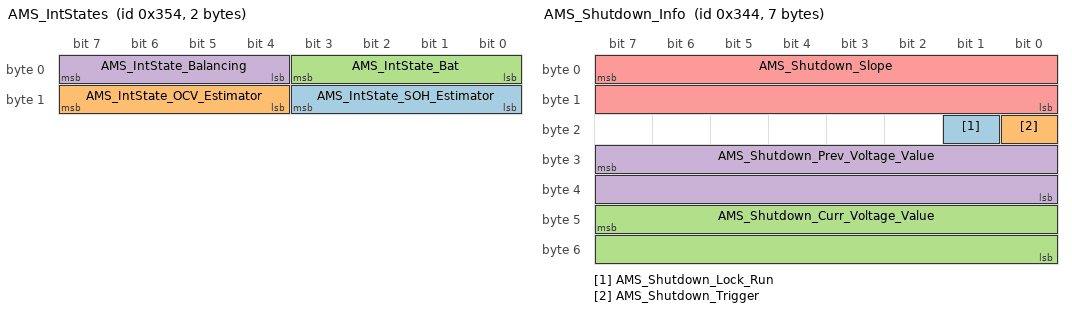
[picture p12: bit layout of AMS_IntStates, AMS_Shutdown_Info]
BO_ 852 AMS_IntStates: 2 _04_HV_AMS
 SG_ AMS_IntState_SOH_Estimator : 8|4@1- (1,0) [0|0] "" Vector__XXX
 SG_ AMS_IntState_OCV_Estimator : 12|4@1- (1,0) [0|0] "" Vector__XXX
 SG_ AMS_IntState_Bat : 0|4@1- (1,0) [0|0] "" Vector__XXX
 SG_ AMS_IntState_Balancing : 4|4@1- (1,0) [0|0] "" Vector__XXX

BO_ 1049 EL_Controller_PI_Controller: 8 _09_ASU
 SG_ EL_Controller_PI_Out : 39|32@0- (0.01,0) [0|0] "" Vector__XXX
 SG_ EL_Controller_PI_In : 7|32@0- (0.01,0) [0|0] "" Vector__XXX

BO_ 836 AMS_Shutdown_Info: 7 _04_HV_AMS
 SG_ AMS_Shutdown_Lock_Run : 17|1@0+ (1,0) [0|0] "" Vector__XXX
 SG_ AMS_Shutdown_Trigger : 16|1@0+ (1,0) [0|0] "" Vector__XXX
 SG_ AMS_Shutdown_Curr_Voltage_Value : 47|16@0+ (1,0) [0|0] "" Vector__XXX
 SG_ AMS_Shutdown_Prev_Voltage_Value : 31|16@0+ (1,0) [0|0] "" Vector__XXX
 SG_ AMS_Shutdown_Slope : 7|16@0- (1,0) [0|0] "" Vector__XXX

BO_ 1033 ASU_SOC: 4 _09_ASU
 SG_ ASU_Terminal_Voltage : 7|16@0- (1,0) [0|0] "mV" Vector__XXX
 SG_ ASU_SOC : 23|16@0- (0.1,0) [0|0] "" Vector__XXX

BO_ 276 AMS_SOC: 8 _04_HV_AMS
 SG_ AMS_SOC_CF : 39|16@0- (0.1,0) [-10|110] "%" Vector__XXX
 SG_ AMS_SOC_OCV : 23|16@0- (0.1,0) [0|0] "%" Vector__XXX
 SG_ AMS_SOC_CC : 7|16@0- (0.1,0) [0|0] "%" Vector__XXX

BO_ 312 Gyro_YawRate: 7 _08_Gyro
 SG_ Gyro_Time_Debug : 48|8@1+ (10,0) [0|0] "us" Vector__XXX
 SG_ Gyro_YawRate_Z : 39|16@0- (0.001,0) [-5|5] "radps" Vector__XXX
 SG_ Gyro_YawRate_Y : 23|16@0- (0.001,0) [-5|5] "radps" Vector__XXX
 SG_ Gyro_YawRate_X : 7|16@0- (0.001,0) [-5|5] "radps" Vector__XXX

BO_ 296 Gyro_Acceleration: 6 _08_Gyro
 SG_ Gyro_Acceleration_Z : 39|16@0- (0.001,0) [-4|4] "g" Vector__XXX
 SG_ Gyro_Acceleration_Y : 23|16@0- (0.001,0) [-4|4] "g" Vector__XXX
 SG_ Gyro_Acceleration_X : 7|16@0- (0.001,0) [-4|4] "g" Vector__XXX

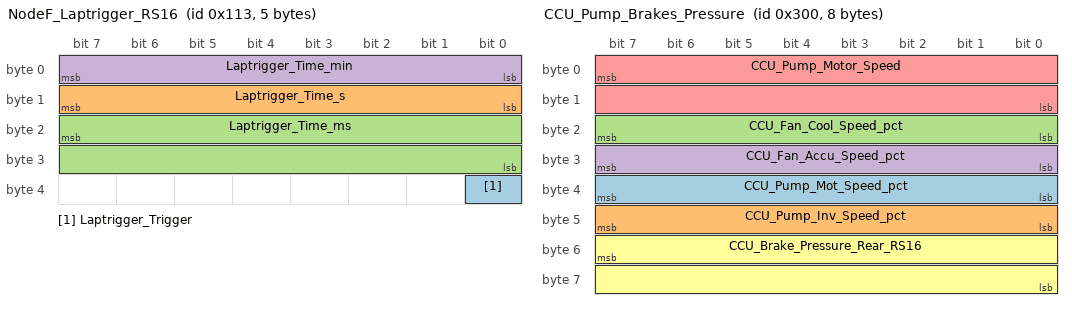
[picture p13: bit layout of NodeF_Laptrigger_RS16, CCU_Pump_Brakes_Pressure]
BO_ 275 NodeF_Laptrigger_RS16: 5 _03_Node_Front
 SG_ Laptrigger_Trigger : 32|1@0+ (1,0) [0|0] "" Vector__XXX
 SG_ Laptrigger_Time_s : 15|8@0+ (1,0) [0|0] "s" Vector__XXX
 SG_ Laptrigger_Time_ms : 23|16@0+ (1,0) [0|0] "ms" Vector__XXX
 SG_ Laptrigger_Time_min : 7|8@0+ (1,0) [0|0] "min" Vector__XXX

BO_ 284 Optical_Sensor_Data_2: 6 _0C_VSU
 SG_ OptSens_Angle : 39|16@0- (0.01,0) [0|0] "°" Vector__XXX
 SG_ OptSens_VT : 23|16@0- (0.01,0) [0|0] "m/s" Vector__XXX
 SG_ OptSens_VL : 7|16@0+ (0.01,0) [0|0] "m/s" Vector__XXX

BO_ 268 Optical_Sensor_Data_1: 8 _0C_VSU
 SG_ OptSens_Distance : 39|32@0+ (0.001,0) [-10|25000] "m" Vector__XXX
 SG_ OptSens_LVL : 23|16@0+ (0.01,0) [-5|35] "m/s" Vector__XXX
 SG_ OptSens_Timestamp : 7|16@0+ (4,0) [0|0] "ms" Vector__XXX

BO_ 1062 LV_AMS_Diagnostic_Data_2: 8 _06_LV_AMS
 SG_ LV_AMS_Temp_Cell_2 : 55|16@0+ (0.1,0) [0|0] "C" Vector__XXX
 SG_ LV_AMS_Voltage_6 : 39|16@0+ (1,0) [2500|4500] "mV" Vector__XXX
 SG_ LV_AMS_Voltage_5 : 23|16@0+ (1,0) [2500|4500] "mV" Vector__XXX
 SG_ LV_AMS_Voltage_4 : 7|16@0+ (1,0) [2500|4500] "mV" Vector__XXX

BO_ 1046 LV_AMS_Diagnostic_Data_1: 8 _06_LV_AMS
 SG_ LV_AMS_Voltage_3 : 55|16@0+ (1,0) [2700|4200] "mV" Vector__XXX
 SG_ LV_AMS_Voltage_2 : 39|16@0+ (1,0) [2700|4200] "mV" Vector__XXX
 SG_ LV_AMS_Voltage_1 : 23|16@0+ (1,0) [2700|4200] "mV" Vector__XXX
 SG_ LV_AMS_Voltage_0 : 7|16@0+ (1,0) [2700|4200] "mV" Vector__XXX

BO_ 534 LV_AMS_SOC_And_Current: 8 _06_LV_AMS
 SG_ LV_AMS_Current_STM : 55|16@0+ (1,0) [0|65535] "" Vector__XXX
 SG_ LV_AMS_SOC : 7|16@0- (1,0) [0|0] "%" Vector__XXX
 SG_ LV_AMS_Capacity : 23|16@0- (0.001,0) [0|0] "Ah" Vector__XXX
 SG_ LV_AMS_Pack_Current_ISL : 39|16@0+ (0.001,0) [0|20] "A" Vector__XXX

BO_ 518 LV_AMS_Voltages: 8 _06_LV_AMS
 SG_ LV_AMS_Voltage_VRGO : 55|16@0+ (1,0) [0|3000] "mV" Vector__XXX
 SG_ LV_AMS_Voltage_VBAT : 39|16@0+ (0.001,0) [0|0] "V" Vector__XXX
 SG_ LV_AMS_Cell_Voltage_Min : 23|16@0+ (1,0) [2700|4200] "mV" Vector__XXX
 SG_ LV_AMS_Cell_Voltage_Max : 7|16@0+ (1,0) [2700|4200] "mV" Vector__XXX

BO_ 768 CCU_Pump_Brakes_Pressure: 8 _00_CCU
 SG_ CCU_Pump_Mot_Speed_pct : 39|8@0+ (1,0) [-10|110] "" Vector__XXX
 SG_ CCU_Pump_Inv_Speed_pct : 47|8@0+ (1,0) [-10|110] "" Vector__XXX
 SG_ CCU_Fan_Cool_Speed_pct : 23|8@0+ (1,0) [0|0] "" Vector__XXX
 SG_ CCU_Fan_Accu_Speed_pct : 31|8@0+ (1,0) [0|0] "" Vector__XXX
 SG_ CCU_Pump_Motor_Speed : 7|16@0+ (1,0) [-10|110] "" Vector__XXX
 SG_ CCU_Brake_Pressure_Rear_RS16 : 55|16@0+ (0.031,-12.693) [0|0] "Bar" Vector__XXX

BO_ 848 CCU_LV_Currents_RS16: 8 _00_CCU
 SG_ CCU_Current_LV_Total_RS16 : 7|16@0+ (0.0122,-24.8) [-5|20] "A" Vector__XXX
 SG_ CCU_Current_LV_Safety_Circuit : 23|16@0+ (0.0122,-24.8) [-5|20] "A" Vector__XXX
 SG_ CCU_Current_LV_Pumps_RS16 : 39|16@0+ (0.0122,-24.8) [-5|20] "A" Vector__XXX
 SG_ CCU_Current_LV_Fans_RS16 : 55|16@0+ (0.0122,-49.6) [-5|20] "A" Vector__XXX

BO_ 800 CCU_Springs: 4 _00_CCU
 SG_ CCU_Spring_RR : 23|16@0+ (0.02442,-27.5885) [0|100] "mm" Vector__XXX
 SG_ CCU_Spring_RL : 7|16@0+ (0.02442,-30.2259) [0|100] "mm" Vector__XXX

BO_ 880 CCU_LV_Voltage: 2 _00_CCU
 SG_ CCU_LV_Voltage : 7|16@0+ (0.01055,0) [0|0] "V" Vector__XXX

BO_ 832 CCU_Temp_Monitoring: 4 _00_CCU
 SG_ CCU_Max_Power_Mod_Temp : 23|16@0+ (0.1,0) [-10|70] "C" Vector__XXX
 SG_ CCU_Max_Motor_Temp : 7|16@0+ (0.1,0) [-10|140] "C" Vector__XXX

BO_ 288 CCU_Monitoring: 5 _00_CCU
 SG_ FM_Optical_RS17 : 33|1@1+ (1,0) [0|0] "" Vector__XXX
 SG_ FM_Saftey_Circuit : 28|1@1+ (1,0) [0|0] "" Vector__XXX
 SG_ FM_Pumps : 27|1@1+ (1,0) [0|0] "" Vector__XXX
 SG_ FM_Inverter_R : 25|1@1+ (1,0) [0|0] "" Vector__XXX
 SG_ FM_Inverter_L : 26|1@1+ (1,0) [0|0] "" Vector__XXX
 SG_ FM_FansCool : 24|1@1+ (1,0) [0|0] "" Vector__XXX
 SG_ FM_FansAccu : 32|1@1+ (1,0) [0|0] "" Vector__XXX
 SG_ FM_Dash : 30|1@1+ (1,0) [0|0] "" Vector__XXX
 SG_ FM_CAN_Nodes : 29|1@1+ (1,0) [0|0] "" Vector__XXX
 SG_ FM_Accu : 31|1@1+ (1,0) [0|0] "" Vector__XXX
 SG_ SM_Wheel_FR : 10|1@1+ (1,0) [0|0] "" Vector__XXX
 SG_ SM_Wheel_FL : 11|1@1+ (1,0) [0|0] "" Vector__XXX
 SG_ SM_Wheel_RR : 8|1@1+ (1,0) [0|0] "" Vector__XXX
 SG_ SM_Wheel_RL : 7|1@1+ (1,0) [0|0] "" Vector__XXX
 SG_ SM_TSMS : 15|1@1+ (1,0) [0|0] "" Vector__XXX
 SG_ SM_SDR : 9|1@1+ (1,0) [0|0] "" Vector__XXX
 SG_ SM_SDL : 5|1@1+ (1,0) [0|0] "" Vector__XXX
 SG_ SM_SDC : 13|1@1+ (1,0) [0|0] "" Vector__XXX
 SG_ SM_LATCHING_RS16 : 4|1@1+ (1,0) [0|0] "" Vector__XXX
 SG_ SM_Inertia : 12|1@1+ (1,0) [0|0] "" Vector__XXX
 SG_ SM_IMD : 0|1@1+ (1,0) [0|0] "" Vector__XXX
 SG_ SM_HVD : 6|1@1+ (1,0) [0|0] "" Vector__XXX
 SG_ SM_CCU : 2|1@1+ (1,0) [0|0] "" Vector__XXX
 SG_ SM_BSPD : 3|1@1+ (1,0) [0|0] "" Vector__XXX
 SG_ SM_BOTS : 14|1@1+ (1,0) [0|0] "" Vector__XXX
 SG_ SM_AMS : 1|1@1+ (1,0) [0|0] "" Vector__XXX
 SG_ SM_Accu : 16|1@1+ (1,0) [0|0] "" Vector__XXX

BO_ 864 CCU_Ambient_Temperature: 2 _00_CCU
 SG_ CCU_Ambient_Temp : 7|16@0+ (0.01,0) [0|0] "C" Vector__XXX

BO_ 1890 NodeP_Temp: 2 _02_Node_Pedal
 SG_ NodeF_Temperature : 7|16@0+ (1,0) [0|0] "" Vector__XXX

BO_ 274 NodeP_Brake_Pressure: 8 _02_Node_Pedal
 SG_ NodeP_Brake_Pressure_Front : 7|16@0+ (0.03157,-12.9) [0|0] "bar" Vector__XXX

BO_ 34 NodeP_Torque_Recup: 8 _02_Node_Pedal
 SG_ NodeP_Torque_2 : 23|16@0+ (1,0) [0|4095] "" Vector__XXX
 SG_ NodeP_Torque_1 : 7|16@0+ (1,0) [0|4095] "" Vector__XXX
 SG_ NodeP_Rekup_2 : 55|16@0+ (1,0) [0|4095] "" Vector__XXX
 SG_ NodeP_Rekup_1 : 39|16@0+ (1,0) [0|4095] "" Vector__XXX

BO_ 803 NodeF_GPS_Status: 8 _03_Node_Front
 SG_ NodeF_GPS_Satelite : 7|8@0+ (1,0) [0|0] "" Vector__XXX
 SG_ NodeF_GPS_Velocity : 23|16@0+ (1,0) [0|0] "" Vector__XXX
 SG_ NodeF_GPS_Signal_Integrity : 15|8@0+ (1,0) [0|0] "" Vector__XXX

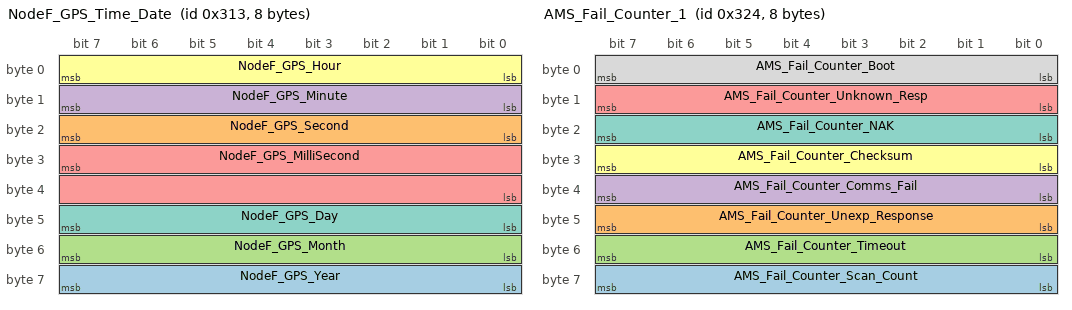
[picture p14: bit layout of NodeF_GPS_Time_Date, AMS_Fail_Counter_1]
BO_ 787 NodeF_GPS_Time_Date: 8 _03_Node_Front
 SG_ NodeF_GPS_Year : 63|8@0+ (1,0) [0|0] "" Vector__XXX
 SG_ NodeF_GPS_Second : 23|8@0+ (1,0) [0|0] "" Vector__XXX
 SG_ NodeF_GPS_Month : 55|8@0+ (1,0) [0|0] "" Vector__XXX
 SG_ NodeF_GPS_Minute : 15|8@0+ (1,0) [0|0] "" Vector__XXX
 SG_ NodeF_GPS_MilliSecond : 31|16@0+ (1,0) [0|0] "" Vector__XXX
 SG_ NodeF_GPS_Hour : 7|8@0+ (1,0) [0|0] "" Vector__XXX
 SG_ NodeF_GPS_Day : 47|8@0+ (1,0) [0|0] "" Vector__XXX

BO_ 771 NodeF_GPS_Long_Lat: 8 _03_Node_Front
 SG_ NodeF_GPS_Longitude : 39|32@0+ (1,0) [0|0] "" Vector__XXX
 SG_ NodeF_GPS_Latitude : 7|32@0+ (1,0) [0|0] "" Vector__XXX

BO_ 515 NodeF_SensorData_1: 8 _03_Node_Front
 SG_ NodeF_Brake_Pressure_Rear_RS17 : 55|16@0+ (0.03157,-12.9) [0|0] "Bar" Vector__XXX
 SG_ NodeF_SteerAngle : 39|16@0+ (0.08373,-211.49) [0|0] "deg" Vector__XXX
 SG_ NodeF_Spring_FR : 23|16@0+ (0.01842,-75.166) [0|100] "mm" Vector__XXX
 SG_ NodeF_Spring_FL : 7|16@0+ (0.01841,-40.658) [0|100] "mm" Vector__XXX

BO_ 1123 NodeF_Temps: 6 _03_Node_Front
 SG_ NodeF_Temperature : 39|16@0+ (1,0) [0|0] "" Vector__XXX

BO_ 804 AMS_Fail_Counter_1: 8 _04_HV_AMS
 SG_ AMS_Fail_Counter_Scan_Count : 63|8@0+ (1,0) [0|10] "" Vector__XXX
 SG_ AMS_Fail_Counter_Unexp_Response : 47|8@0+ (1,0) [0|10] "" Vector__XXX
 SG_ AMS_Fail_Counter_Timeout : 55|8@0+ (1,0) [0|10] "" Vector__XXX
 SG_ AMS_Fail_Counter_Comms_Fail : 39|8@0+ (1,0) [0|10] "" Vector__XXX
 SG_ AMS_Fail_Counter_Unknown_Resp : 15|8@0+ (1,0) [0|10] "" Vector__XXX
 SG_ AMS_Fail_Counter_Checksum : 31|8@0+ (1,0) [0|10] "" Vector__XXX
 SG_ AMS_Fail_Counter_NAK : 23|8@0+ (1,0) [0|10] "" Vector__XXX
 SG_ AMS_Fail_Counter_Boot : 7|8@0+ (1,0) [0|10] "" Vector__XXX

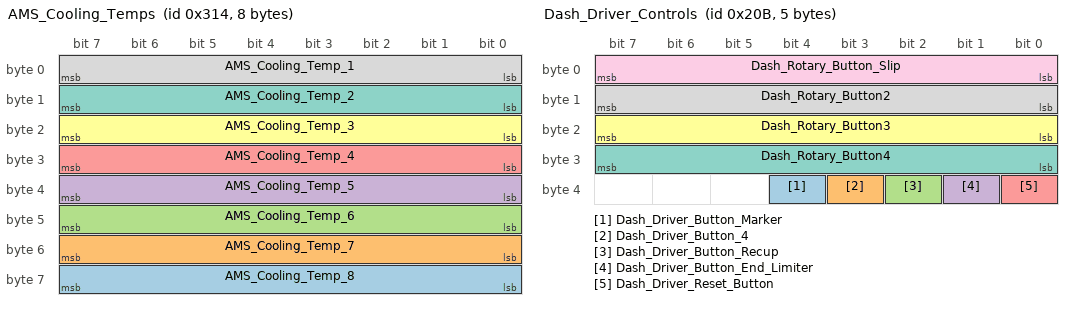
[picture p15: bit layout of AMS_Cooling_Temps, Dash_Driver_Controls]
BO_ 788 AMS_Cooling_Temps: 8 _04_HV_AMS
 SG_ AMS_Cooling_Temp_8 : 63|8@0+ (1,0) [0|0] "C" Vector__XXX
 SG_ AMS_Cooling_Temp_7 : 55|8@0+ (1,0) [0|0] "C" Vector__XXX
 SG_ AMS_Cooling_Temp_6 : 47|8@0+ (1,0) [0|0] "C" Vector__XXX
 SG_ AMS_Cooling_Temp_5 : 39|8@0+ (1,0) [0|0] "C" Vector__XXX
 SG_ AMS_Cooling_Temp_4 : 31|8@0+ (1,0) [0|0] "C" Vector__XXX
 SG_ AMS_Cooling_Temp_3 : 23|8@0+ (1,0) [0|0] "C" Vector__XXX
 SG_ AMS_Cooling_Temp_2 : 15|8@0+ (1,0) [0|0] "C" Vector__XXX
 SG_ AMS_Cooling_Temp_1 : 7|8@0+ (1,0) [0|0] "C" Vector__XXX

BO_ 324 AMS_Temps: 8 _04_HV_AMS
 SG_ AMS_Temp_Master_PCB : 55|16@0- (0.1,0) [0|0] "" Vector__XXX
 SG_ AMS_Cell_Temp_Min : 39|16@0- (0.1,0) [0|0] "C" Vector__XXX
 SG_ AMS_Cell_Temp_Max : 7|16@0- (0.1,0) [0|65] "C" Vector__XXX
 SG_ AMS_Cell_Temp_Avg : 23|16@0- (0.1,0) [0|65] "C" Vector__XXX

BO_ 308 AMS_Voltages: 8 _04_HV_AMS
 SG_ AMS_PackVoltage : 7|16@0+ (0.1,0) [388|610] "V" Vector__XXX
 SG_ AMS_Cell_Voltage_Min : 39|16@0- (1,0) [2700|4200] "mV" Vector__XXX
 SG_ AMS_Cell_Voltage_Max : 23|16@0- (1,0) [2700|4200] "mV" Vector__XXX
 SG_ AMS_Cell_Voltage_Avg : 55|16@0- (1,0) [2700|4200] "mV" Vector__XXX

BO_ 523 Dash_Driver_Controls: 5 _0B_Dash
 SG_ Dash_Driver_Button_Marker : 36|1@0+ (1,0) [0|0] "" Vector__XXX
 SG_ Dash_Driver_Button_4 : 35|1@0+ (1,0) [0|0] "" Vector__XXX
 SG_ Dash_Driver_Button_Recup : 34|1@0+ (1,0) [0|0] "" Vector__XXX
 SG_ Dash_Driver_Button_End_Limiter : 33|1@0+ (1,0) [0|0] "" Vector__XXX
 SG_ Dash_Driver_Reset_Button : 32|1@0+ (1,0) [0|0] "" Vector__XXX
 SG_ Dash_Rotary_Button3 : 23|8@0+ (1,0) [0|15] "" Vector__XXX
 SG_ Dash_Rotary_Button4 : 31|8@0+ (1,0) [0|10] "" Vector__XXX
 SG_ Dash_Rotary_Button2 : 15|8@0+ (1,0) [0|10] "" Vector__XXX
 SG_ Dash_Rotary_Button_Slip : 7|8@0+ (1,0) [0|10] "" Vector__XXX

BO_ 1125 TCU_Buffers: 8 _05_TCU
 SG_ Tel_Short_Buffer_Len : 23|16@0+ (1,0) [0|0] "" Vector__XXX
 SG_ Tel_Long_Buffer_Len : 7|16@0+ (1,0) [0|0] "" Vector__XXX

BO_ 1095 Shunt_Response_Stop: 8 _07_Shunt

BO_ 1111 Shunt_Command: 8 _07_Shunt

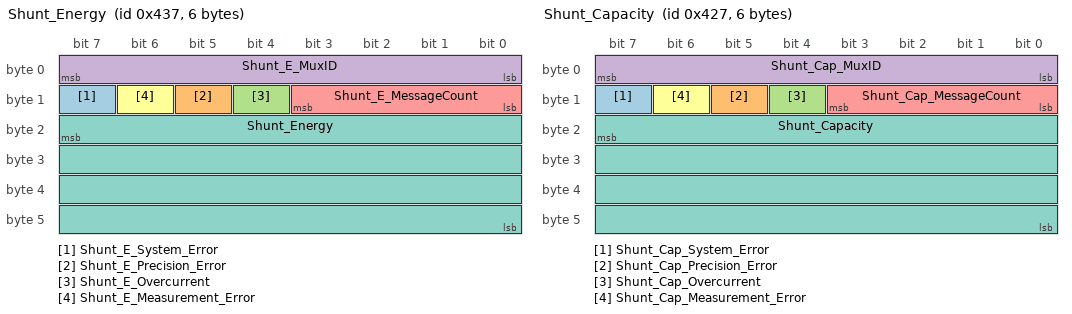
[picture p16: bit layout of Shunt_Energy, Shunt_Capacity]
BO_ 1079 Shunt_Energy: 6 _07_Shunt
 SG_ Shunt_E_System_Error : 15|1@0+ (1,0) [0|1] "" Vector__XXX
 SG_ Shunt_E_Precision_Error : 13|1@0+ (1,0) [0|1] "" Vector__XXX
 SG_ Shunt_E_Overcurrent : 12|1@0+ (1,0) [0|1] "" Vector__XXX
 SG_ Shunt_E_MuxID : 7|8@0+ (1,0) [0|7] "" Vector__XXX
 SG_ Shunt_E_MessageCount : 11|4@0+ (1,0) [0|15] "" Vector__XXX
 SG_ Shunt_E_Measurement_Error : 14|1@0+ (1,0) [0|1] "" Vector__XXX
 SG_ Shunt_Energy : 23|32@0- (1,0) [0|0] "Wh" Vector__XXX

BO_ 1063 Shunt_Capacity: 6 _07_Shunt
 SG_ Shunt_Cap_System_Error : 15|1@0+ (1,0) [0|1] "" Vector__XXX
 SG_ Shunt_Cap_Precision_Error : 13|1@0+ (1,0) [0|1] "" Vector__XXX
 SG_ Shunt_Cap_Overcurrent : 12|1@0+ (1,0) [0|1] "" Vector__XXX
 SG_ Shunt_Cap_MuxID : 7|8@0+ (1,0) [0|7] "" Vector__XXX
 SG_ Shunt_Cap_MessageCount : 11|4@0+ (1,0) [0|15] "" Vector__XXX
 SG_ Shunt_Cap_Measurement_Error : 14|1@0+ (1,0) [0|1] "" Vector__XXX
 SG_ Shunt_Capacity : 23|32@0- (0.000277777,0) [0|0] "Ah" Vector__XXX

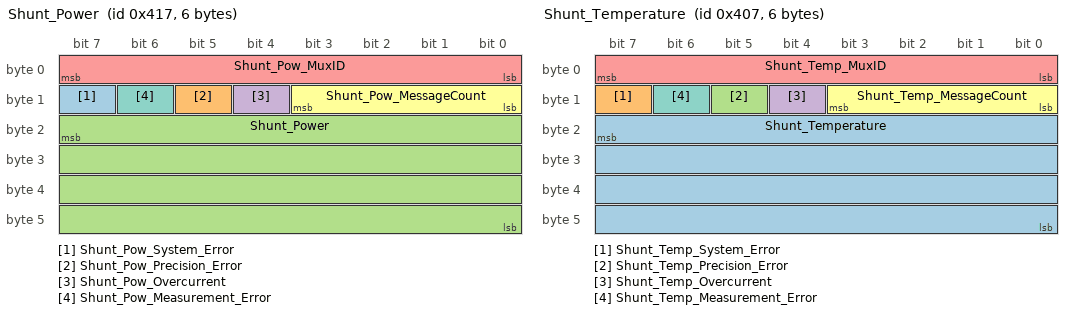
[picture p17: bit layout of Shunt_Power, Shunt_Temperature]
BO_ 1047 Shunt_Power: 6 _07_Shunt
 SG_ Shunt_Pow_System_Error : 15|1@0+ (1,0) [0|1] "" Vector__XXX
 SG_ Shunt_Pow_Precision_Error : 13|1@0+ (1,0) [0|1] "" Vector__XXX
 SG_ Shunt_Power : 23|32@0- (0.001,0) [-110|110] "kW" Vector__XXX
 SG_ Shunt_Pow_Overcurrent : 12|1@0+ (1,0) [0|1] "" Vector__XXX
 SG_ Shunt_Pow_MuxID : 7|8@0+ (1,0) [0|7] "" Vector__XXX
 SG_ Shunt_Pow_MessageCount : 11|4@0+ (1,0) [0|15] "" Vector__XXX
 SG_ Shunt_Pow_Measurement_Error : 14|1@0+ (1,0) [0|1] "" Vector__XXX

BO_ 1031 Shunt_Temperature: 6 _07_Shunt
 SG_ Shunt_Temperature : 23|32@0- (0.1,0) [0|100] "C" Vector__XXX
 SG_ Shunt_Temp_System_Error : 15|1@0+ (1,0) [0|1] "" Vector__XXX
 SG_ Shunt_Temp_Precision_Error : 13|1@0+ (1,0) [0|1] "" Vector__XXX
 SG_ Shunt_Temp_Overcurrent : 12|1@0+ (1,0) [0|1] "" Vector__XXX
 SG_ Shunt_Temp_MuxID : 7|8@0+ (1,0) [0|7] "" Vector__XXX
 SG_ Shunt_Temp_MessageCount : 11|4@0+ (1,0) [0|15] "" Vector__XXX
 SG_ Shunt_Temp_Measurement_Error : 14|1@0+ (1,0) [0|1] "" Vector__XXX

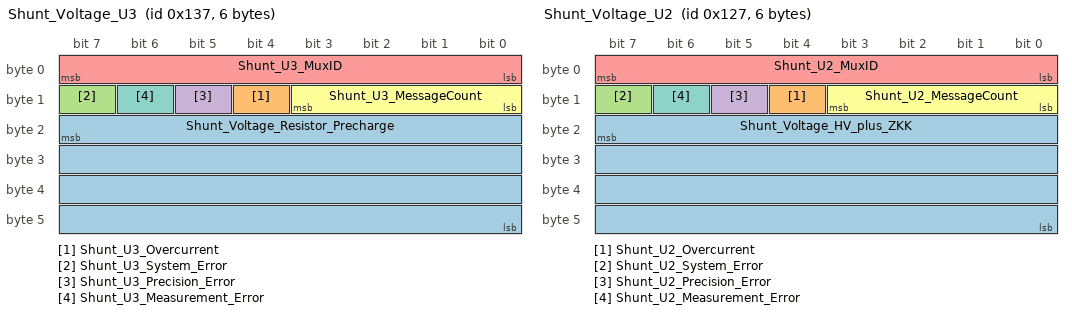
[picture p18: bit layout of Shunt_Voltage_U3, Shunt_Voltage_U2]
BO_ 311 Shunt_Voltage_U3: 6 _07_Shunt
 SG_ Shunt_Voltage_Resistor_Precharge : 23|32@0- (0.001,0) [-50|650] "V" Vector__XXX
 SG_ Shunt_U3_Overcurrent : 12|1@0+ (1,0) [0|1] "" Vector__XXX
 SG_ Shunt_U3_System_Error : 15|1@0+ (1,0) [0|1] "" Vector__XXX
 SG_ Shunt_U3_Precision_Error : 13|1@0+ (1,0) [0|1] "" Vector__XXX
 SG_ Shunt_U3_MuxID : 7|8@0+ (1,0) [0|7] "" Vector__XXX
 SG_ Shunt_U3_MessageCount : 11|4@0+ (1,0) [0|15] "" Vector__XXX
 SG_ Shunt_U3_Measurement_Error : 14|1@0+ (1,0) [0|1] "" Vector__XXX

BO_ 295 Shunt_Voltage_U2: 6 _07_Shunt
 SG_ Shunt_Voltage_HV_plus_ZKK : 23|32@0- (0.001,0) [-50|650] "V" Vector__XXX
 SG_ Shunt_U2_Overcurrent : 12|1@0+ (1,0) [0|1] "" Vector__XXX
 SG_ Shunt_U2_System_Error : 15|1@0+ (1,0) [0|1] "" Vector__XXX
 SG_ Shunt_U2_Precision_Error : 13|1@0+ (1,0) [0|1] "" Vector__XXX
 SG_ Shunt_U2_MuxID : 7|8@0+ (1,0) [0|7] "" Vector__XXX
 SG_ Shunt_U2_MessageCount : 11|4@0+ (1,0) [0|15] "" Vector__XXX
 SG_ Shunt_U2_Measurement_Error : 14|1@0+ (1,0) [0|1] "" Vector__XXX

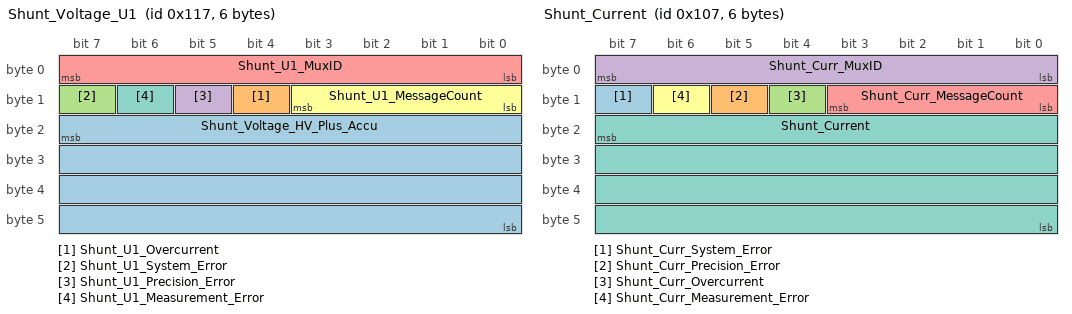
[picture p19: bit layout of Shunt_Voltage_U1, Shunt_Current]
BO_ 279 Shunt_Voltage_U1: 6 _07_Shunt
 SG_ Shunt_Voltage_HV_Plus_Accu : 23|32@0- (0.001,0) [-50|650] "V" Vector__XXX
 SG_ Shunt_U1_Overcurrent : 12|1@0+ (1,0) [0|1] "" Vector__XXX
 SG_ Shunt_U1_System_Error : 15|1@0+ (1,0) [0|1] "" Vector__XXX
 SG_ Shunt_U1_Precision_Error : 13|1@0+ (1,0) [0|1] "" Vector__XXX
 SG_ Shunt_U1_MuxID : 7|8@0+ (1,0) [0|7] "" Vector__XXX
 SG_ Shunt_U1_MessageCount : 11|4@0+ (1,0) [0|15] "" Vector__XXX
 SG_ Shunt_U1_Measurement_Error : 14|1@0+ (1,0) [0|1] "" Vector__XXX

BO_ 263 Shunt_Current: 6 _07_Shunt
 SG_ Shunt_Curr_System_Error : 15|1@0+ (1,0) [0|1] "" Vector__XXX
 SG_ Shunt_Curr_Precision_Error : 13|1@0+ (1,0) [0|1] "" Vector__XXX
 SG_ Shunt_Curr_Overcurrent : 12|1@0+ (1,0) [0|1] "" Vector__XXX
 SG_ Shunt_Curr_MuxID : 7|8@0+ (1,0) [0|7] "" Vector__XXX
 SG_ Shunt_Curr_MessageCount : 11|4@0+ (1,0) [0|15] "" Vector__XXX
 SG_ Shunt_Curr_Measurement_Error : 14|1@0+ (1,0) [0|1] "" Vector__XXX
 SG_ Shunt_Current : 23|32@0- (0.001,0) [-210|210] "A" Vector__XXX

BO_ 300 Optical_Sensor_Status: 8 _0C_VSU
 SG_ OptSens_LED_Current : 40|8@1- (0.01,0) [0|0] "A" Vector__XXX
 SG_ OptSens_Temperature : 32|8@1- (1,0) [0|0] "C" Vector__XXX
 SG_ OptSens_Sensor_Number : 24|8@1- (1,0) [0|0] "" Vector__XXX
 SG_ OptSens_Serial_Number : 7|24@0- (1,0) [0|0] "" Vector__XXX
 SG_ OptSens_VEE_OK : 61|1@1+ (1,0) [0|0] "" Vector__XXX
 SG_ OptSens_VDD_OK : 62|1@1+ (1,0) [0|0] "" Vector__XXX
 SG_ OptSens_V33_OK : 60|1@1+ (1,0) [0|0] "" Vector__XXX
 SG_ OptSens_V25_OK : 59|1@1+ (1,0) [0|0] "" Vector__XXX
 SG_ OptSens_Voltage_OK : 55|1@1+ (1,0) [0|0] "" Vector__XXX
 SG_ OptSens_Current_OK : 54|1@1+ (1,0) [0|0] "" Vector__XXX
 SG_ OptSens_Current_High_Low : 53|1@1+ (1,0) [0|0] "" Vector__XXX
 SG_ OptSens_Optic_OK : 52|1@1+ (1,0) [0|0] "" Vector__XXX
 SG_ OptSens_Temperature_OK : 51|1@1+ (1,0) [0|0] "" Vector__XXX
 SG_ OptSens_Sensor_OK : 50|1@1+ (1,0) [0|0] "" Vector__XXX
 SG_ OptSens_Selftest_Flag : 49|1@1+ (1,0) [0|0] "" Vector__XXX
 SG_ OptSens_STST_bit : 48|1@1+ (1,0) [0|0] "" Vector__XXX
 SG_ OptSens_LED_Status_Bit_1 : 58|1@1+ (1,0) [0|0] "" Vector__XXX
 SG_ OptSens_LED_Status_Bit_0 : 57|1@1+ (1,0) [0|0] "" Vector__XXX
 SG_ OptSens_LED_Cal : 56|1@1+ (1,0) [0|0] "" Vector__XXX

BO_ 685 Tire_Temp_FL: 6 _0D_TSU_F
 SG_ Tire_Temp_FR_Outer : 7|16@0+ (0.061,-25) [0|200] "C" Vector__XXX
 SG_ Tire_Temp_FR_Middle : 23|16@0+ (0.061,-25) [0|200] "C" Vector__XXX
 SG_ Tire_Temp_FR_Inner : 39|16@0+ (0.061,-25) [0|200] "C" Vector__XXX

BO_ 718 Tire_Temp_RR: 6 _0E_TSU_R
 SG_ Tire_Temp_RR_Outer : 7|16@0+ (0.041,-13.33) [0|200] "C" Vector__XXX
 SG_ Tire_Temp_RR_Middle : 23|16@0+ (0.041,-13.33) [0|200] "C" Vector__XXX
 SG_ Tire_Temp_RR_Inner : 39|16@0+ (0.041,-13.33) [0|200] "C" Vector__XXX

BO_ 702 Tire_Temp_RL: 6 _0E_TSU_R
 SG_ Tire_Temp_RL_Outer : 7|16@0+ (0.041,-13.33) [0|200] "C" Vector__XXX
 SG_ Tire_Temp_RL_Middle : 23|16@0+ (0.041,-13.33) [0|200] "C" Vector__XXX
 SG_ Tire_Temp_RL_Inner : 39|16@0+ (0.041,-13.33) [0|200] "C" Vector__XXX

BO_ 669 Tire_Temp_FR: 6 _0D_TSU_F
 SG_ Tire_Temp_FL_Outer : 7|16@0+ (0.061,-25) [0|200] "C" Vector__XXX
 SG_ Tire_Temp_FL_Middle : 23|16@0+ (0.061,-25) [0|200] "C" Vector__XXX
 SG_ Tire_Temp_FL_Inner : 39|16@0+ (0.061,-25) [0|200] "C" Vector__XXX

BO_ 1893 Config_Tel_Write_LV_AMS: 8 _05_TCU
 SG_ LV_AMS_Config_Value_W : 23|16@0+ (1,0) [0|0] "" Vector__XXX
 SG_ LV_AMS_Config_ID_W : 7|16@0+ (1,0) [0|0] "" Vector__XXX

BO_ 1637 Config_Tel_Read_LV_AMS: 8 _05_TCU
 SG_ LV_AMS_Config_Value_RD : 23|16@0+ (1,0) [0|0] "" Vector__XXX
 SG_ LV_AMS_Config_ID_RD : 7|16@0+ (1,0) [0|0] "" Vector__XXX

BO_ 1622 Config_Tel_Response_LV_AMS: 8 _06_LV_AMS
 SG_ LV_AMS_Config_Value_RX : 23|16@0+ (1,0) [0|0] "" Vector__XXX
 SG_ LV_AMS_Config_ID_RX : 7|16@0+ (1,0) [0|0] "" Vector__XXX

BO_ 1845 Config_Tel_Write_Node_F: 8 _05_TCU
 SG_ Node_F_Config_Value_W : 23|16@0+ (1,0) [0|0] "" Vector__XXX
 SG_ Node_F_Config_ID_W : 7|16@0+ (1,0) [0|0] "" Vector__XXX

BO_ 1631 Config_Tel_Response_Node_Deflt: 8 _0F_Node_Dflt
 SG_ Node_Deflt_Config_Value_RX : 23|16@0+ (1,0) [0|0] "" Vector__XXX
 SG_ Node_Deflt_Config_ID_RX : 7|16@0+ (1,0) [0|0] "" Vector__XXX

BO_ 1781 Config_Tel_Read_Node_Deflt: 8 _05_TCU
 SG_ Node_Deflt_Config_Value_RD : 23|16@0+ (1,0) [0|0] "" Vector__XXX
 SG_ Node_Deflt_Config_ID_RD : 7|16@0+ (1,0) [0|0] "" Vector__XXX

BO_ 1619 Config_Tel_Response_Node_F: 8 _03_Node_Front
 SG_ Node_F_Config_Value_RX : 23|16@0+ (1,0) [0|0] "" Vector__XXX
 SG_ Node_F_Config_ID_RX : 7|16@0+ (1,0) [0|0] "" Vector__XXX

BO_ 1618 Config_Tel_Response_Node_Ped: 8 _02_Node_Pedal
 SG_ Node_Ped_Config_Value_RX : 23|16@0+ (1,0) [0|0] "" Vector__XXX
 SG_ Node_Ped_Config_ID_RX : 7|16@0+ (1,0) [0|0] "" Vector__XXX

BO_ 1861 Config_Tel_Write_AMS: 4 _05_TCU
 SG_ AMS_Config_Value_W : 23|16@0+ (1,0) [0|0] "" Vector__XXX
 SG_ AMS_Config_ID_W : 7|16@0+ (1,0) [0|0] "" Vector__XXX

BO_ 1829 Config_Tel_Write_Node_Ped: 8 _05_TCU
 SG_ Node_Ped_Config_Value_W : 23|16@0+ (1,0) [0|0] "" Vector__XXX
 SG_ Node_Ped_Config_ID_W : 7|16@0+ (1,0) [0|0] "" Vector__XXX

BO_ 1813 Config_Tel_Write_MCU: 8 _05_TCU
 SG_ MCU_Config_Value_W : 23|16@0+ (1,0) [0|0] "" Vector__XXX
 SG_ MCU_Config_ID_W : 7|16@0+ (1,0) [0|0] "" Vector__XXX

BO_ 1797 Config_Tel_Write_CCU: 8 _05_TCU
 SG_ CCU_Config_Value_W : 23|16@0+ (1,0) [0|0] "" Vector__XXX
 SG_ CCU_Config_ID_W : 7|16@0+ (1,0) [0|0] "" Vector__XXX

BO_ 1620 Config_Tel_Response_AMS: 8 _04_HV_AMS
 SG_ AMS_Config_Value_RX : 23|16@0+ (1,0) [0|0] "" Vector__XXX
 SG_ AMS_Config_ID_RX : 7|16@0+ (1,0) [0|0] "" Vector__XXX

BO_ 1617 Config_Tel_Response_MCU: 8 _01_MCU
 SG_ MCU_Config_Value_RX : 23|16@0+ (1,0) [0|0] "" Vector__XXX
 SG_ MCU_Config_ID_RX : 7|16@0+ (1,0) [0|0] "" Vector__XXX

BO_ 1616 Config_Tel_Response_CCU: 8 _00_CCU
 SG_ CCU_Config_Value_RX : 23|16@0+ (1,0) [0|0] "" Vector__XXX
 SG_ CCU_Config_ID_RX : 7|16@0+ (1,0) [0|0] "" Vector__XXX

BO_ 1605 Config_Tel_Read_AMS: 8 _05_TCU
 SG_ AMS_Config_Value_RD : 23|16@0+ (1,0) [0|0] "" Vector__XXX
 SG_ AMS_Config_ID_RD : 7|16@0+ (1,0) [0|0] "" Vector__XXX

BO_ 1589 Config_Tel_Read_Node_F: 8 _05_TCU
 SG_ Node_F_Config_Value_RD : 23|16@0+ (1,0) [0|0] "" Vector__XXX
 SG_ Node_F_Config_ID_RD : 7|16@0+ (1,0) [0|0] "" Vector__XXX

BO_ 1573 Config_Tel_Read_Node_Ped: 8 _05_TCU
 SG_ Node_Ped_Config_Value_RD : 23|16@0+ (1,0) [0|0] "" Vector__XXX
 SG_ Node_Ped_Config_ID_RD : 7|16@0+ (1,0) [0|0] "" Vector__XXX

BO_ 1557 Config_Tel_Read_MCU: 8 _05_TCU
 SG_ MCU_Config_Value_RD : 23|16@0+ (1,0) [0|0] "" Vector__XXX
 SG_ MCU_Config_ID_RD : 7|16@0+ (1,0) [0|0] "" Vector__XXX

BO_ 1541 Config_Tel_Read_CCU: 8 _05_TCU
 SG_ CCU_Config_Value_RD : 23|16@0+ (1,0) [0|0] "" Vector__XXX
 SG_ CCU_Config_ID_RD : 7|16@0+ (1,0) [0|0] "" Vector__XXX

BO_ 2037 Config_Tel_Write_Node_Deflt: 8 _05_TCU
 SG_ Node_Deflt_Cfg_Tel_ID_W : 7|16@0+ (1,0) [0|0] "" Vector__XXX
 SG_ Node_Deflt_Cfg_Seq_Nr_W : 16|8@1- (1,0) [0|0] "" Vector__XXX

EV_ EnvVar_AMS_SOC_CC: 0 [0|256] "" 0 1 DUMMY_NODE_VECTOR0 Vector__XXX;

EV_ EnvVar_LV_AMS_BalState: 0 [0|0] "" 0 2 DUMMY_NODE_VECTOR8000 Vector__XXX;

EV_ EnvVar_AMS_Status_OK: 0 [0|0] "" 0 3 DUMMY_NODE_VECTOR0 Vector__XXX;

EV_ EnvVar_AMS_Status_Enabled: 0 [0|0] "" 0 4 DUMMY_NODE_VECTOR0 Vector__XXX;

EV_ EnvVar_AMS_PM_Air2: 0 [0|0] "" 0 5 DUMMY_NODE_VECTOR0 Vector__XXX;

EV_ EnvVar_AMS_Flags_Enabled: 0 [0|0] "" 0 6 DUMMY_NODE_VECTOR0 Vector__XXX;

EV_ EnvVar_AMS_SOC_CF: 0 [0|0] "" 0 7 DUMMY_NODE_VECTOR0 Vector__XXX;

EV_ EnvVar_AMS_SOC_Enabled: 0 [0|0] "" 0 8 DUMMY_NODE_VECTOR0 Vector__XXX;

EV_ EnvVar_OptSens_Status_Sensor_OK: 0 [0|0] "" 0 9 DUMMY_NODE_VECTOR0 Vector__XXX;

EV_ EnvVar_OptSens_Status_Enabled: 0 [0|0] "" 0 10 DUMMY_NODE_VECTOR0 Vector__XXX;

EV_ EnvVar_AMS_BalState: 0 [0|0] "" 0 11 DUMMY_NODE_VECTOR8000 Vector__XXX;

EV_ EnvVar_AMS_Opmode: 0 [0|0] "" 0 12 DUMMY_NODE_VECTOR8000 Vector__XXX;

EV_ EnvVar_VSU_Distance: 0 [0|0] "" 0 13 DUMMY_NODE_VECTOR0 Vector__XXX;

EV_ EnvVar_VSU_Distance_Enabled: 0 [0|1] "" 0 14 DUMMY_NODE_VECTOR0 Vector__XXX;

EV_ EnvVar_AMS_Cell_Voltage_Max: 0 [0|0] "" 0 15 DUMMY_NODE_VECTOR0 Vector__XXX;

EV_ EnvVar_Shunt_Power_Enabled: 0 [0|1] "" 0 16 DUMMY_NODE_VECTOR0 Vector__XXX;

EV_ EnvVar_Shunt_Power: 0 [0|256] "" 0 17 DUMMY_NODE_VECTOR0 Vector__XXX;

EV_ EnvVar_Cell_Temp_Max_Enabled: 0 [0|1] "" 0 18 DUMMY_NODE_VECTOR0 Vector__XXX;

EV_ EnvVar_Cell_Temp_Max: 0 [0|0] "" 0 19 DUMMY_NODE_VECTOR0 Vector__XXX;

EV_ EnvVar_AMS_Voltages_Enabled: 0 [0|0] "" 0 20 DUMMY_NODE_VECTOR0 Vector__XXX;

EV_ EnvVar_AMS_Packvoltage: 0 [0|1536] "" 0 21 DUMMY_NODE_VECTOR0 Vector__XXX;

EV_ EnvVar_OptSens_Speed_Enabled: 0 [0|1] "" 0 22 DUMMY_NODE_VECTOR0 Vector__XXX;

EV_ EnvVar_OptSens_Speed: 0 [0|512] "" 0 23 DUMMY_NODE_VECTOR0 Vector__XXX;

EV_ EnvVar_Shunt_Voltage_Enabled: 0 [0|0] "" 0 24 DUMMY_NODE_VECTOR0 Vector__XXX;

EV_ EnvVar_Shunt_Voltage: 0 [0|0] "" 0 25 DUMMY_NODE_VECTOR0 Vector__XXX;

EV_ EnvVar_Shunt_Current_Enabled: 0 [0|1] "" 0 26 DUMMY_NODE_VECTOR0 Vector__XXX;

EV_ EnvVar_Shunt_Current: 0 [-512|512] "" 0 27 DUMMY_NODE_VECTOR0 Vector__XXX;

CM_ BO_ 3221225472 "This is a message for not used signals, created by Vector CANdb++ DBC OLE DB Provider.";
CM_ BO_ 1111 "Function commands, SET and GET commands.
A command-ID-byte is included for identification.";
CM_ SG_ 1079 Shunt_Energy "referring to current and voltage U1";
CM_ BO_ 1047 "referring to current and voltage U1";
VAL_ 3221225472 Status 8 "Error" 7 "Logging EM & FSD data" 5 "Logging FSD data" 3 "Logging EM data" 1 "DL idle, ready to log" ;
VAL_ 389 AERO_Range_R 3 "600-1100mBar" 2 "Differential" 1 "600-1200mBar" 0 "200-1200mBar" ;
VAL_ 386 AERO_Range_F 3 "600-1100mBar" 2 "Differential" 1 "600-1200mBar" 0 "200-1200mBar" ;
VAL_ 928 CCU_IMD_Startup_Check 2 "Undefined" 1 "Error" 0 "OK" ;
VAL_ 928 CCU_IMD_Short_Circuit_Plus 2 "Undefined" 1 "Error" 0 "OK" ;
VAL_ 928 CCU_IMD_Short_Circuit_Minus 2 "Undefined" 1 "Error" 0 "OK" ;
VAL_ 928 CCU_IMD_Ground_Error 2 "Undefined" 1 "Error" 0 "OK" ;
VAL_ 928 CCU_IMD_Device_Error 2 "Undefined" 1 "Error" 0 "OK" ;
VAL_ 1110 LV_AMS_I2C_State_Machine 4 "ShutdownPending" 3 "ManualRunning" 2 "ManualInit" 1 "Running" 0 "Init" ;
VAL_ 532 AMS_IMD_Startup_Check 2 "Undefined" 1 "Error" 0 "OK" ;
VAL_ 532 AMS_IMD_Short_Circuit_Plus 2 "Undefined" 1 "Error" 0 "OK" ;
VAL_ 532 AMS_IMD_Short_Circuit_Minus 2 "Undefined" 1 "Error" 0 "OK" ;
VAL_ 532 AMS_IMD_Ground_Error 2 "Undefined" 1 "Error" 0 "OK" ;
VAL_ 532 AMS_IMD_Device_Error 2 "Undefined" 1 "Error" 0 "OK" ;
VAL_ 852 AMS_IntState_SOH_Estimator 3 "State_Reset" 2 "State_Running" 1 "State_Wait_For_Run" 0 "State_Init" ;
VAL_ 852 AMS_IntState_OCV_Estimator 3 "State_Reset" 2 "State_Running" 1 "State_Wait_For_Run" 0 "State_Init" ;
VAL_ 852 AMS_IntState_Bat 2 "State_Recalibrate" 1 "State_Load_Applied" 0 "State_Bat_Relaxed" ;
VAL_ 852 AMS_IntState_Balancing 3 "State_Finished" 2 "State_Cool_Down" 1 "State_Active" 0 "State_Init" ;
VAL_ 1813 MCU_Config_ID_W 45 "Brake pessure RTD limit" 44 "Brake Pressure plausibility lim" 43 "Recup ENC full at position" 42 "Brake pedal lower mech lim" 41 "Torque pedal upper mech lim" 40 "Torque pedal kickdown start" 39 "Torque pedal lower mech lim" 38 "Torque pedal mechanical tol" 37 "Set total distance recorder (!)" 36 "Inverter calibration mode" 35 "Traction Control T_Rear" 34 "Traction Control T_Front" 33 "Taction Control Kp" 32 "MCU speed controller Kp" 31 "Torque graph end derivation" 30 "Torque graph start derivation" 29 "Torque Vectoring exponent" 28 "Recup Vectoring max neg shift R" 27 "Recup Vectoring max pos shift R" 26 "Recup Vectoring max neg shift F" 25 "Recup Vectoring max pos shift F" 24 "Torque Vectoring max neg shift R" 23 "Torque Vectoring max pos shift R" 22 "Torque Vectoring max neg shift F" 21 "Torque Vectoring max pos shift F" 20 "Engine Brake" 19 "Torque Vectoring 100% steerangle" 18 "Recup ENC weight" 17 "Recup BP weight" 16 "Maximum recuperation current" 15 "Recup BP at full brake pressure" 14 "Maximum recup rear" 13 "Maximum recup front" 12 "Maximum torque rear" 11 "Maximum torque front" 10 "Maximum RPM Inverter" 9 "Maximum RPM controlled by MCU" 8 "Maximum power" 7 "Endurance Limiter maximum SoC" 6 "Endurance Limiter minimum SoC" 5 "Endurance Limiter enabled" 4 "Traction Control enabled" 3 "Engine Brake enabled" 2 "Torque Vectoring enabled" 1 "Recuperation enabled" 0 "Reset Flash" ;
VAL_ 1797 CCU_Config_ID_W 15 "Voltage pump right" 14 "Voltage pump left" 13 "Laptrigger enabled (reboot)" 12 "Control eFuse Inverter right" 11 "Control eFuse Inverter left" 10 "Control eFuse Accumulator" 9 "Control eFuse CAN node" 8 "Torque pedal max way (mech lim)" 7 "Torque pedal full way (kickdown)" 6 "DRS mode" 5 "Fan Cooling manual speed" 4 "Fan Accu manual speed" 3 "Pump Inverter manual speed" 2 "Pump Motor manual speed" 1 "Cool mode" 0 "Reset Flash" ;
VAL_ 1617 MCU_Config_ID_RX 45 "Brake pessure RTD limit" 44 "Brake Pressure plausibility lim" 43 "Recup ENC full at position" 42 "Brake pedal lower mech lim" 41 "Torque pedal upper mech lim" 40 "Torque pedal kickdown start" 39 "Torque pedal lower mech lim" 38 "Torque pedal mechanical tol" 37 "Set total distance recorder (!)" 36 "Inverter calibration mode" 35 "Traction Control T_Rear" 34 "Traction Control T_Front" 33 "Taction Control Kp" 32 "MCU speed controller Kp" 31 "Torque graph end derivation" 30 "Torque graph start derivation" 29 "Torque Vectoring exponent" 28 "Recup Vectoring max neg shift R" 27 "Recup Vectoring max pos shift R" 26 "Recup Vectoring max neg shift F" 25 "Recup Vectoring max pos shift F" 24 "Torque Vectoring max neg shift R" 23 "Torque Vectoring max pos shift R" 22 "Torque Vectoring max neg shift F" 21 "Torque Vectoring max pos shift F" 20 "Engine Brake" 19 "Torque Vectoring 100% steerangle" 18 "Recup ENC weight" 17 "Recup BP weight" 16 "Maximum recuperation current" 15 "Recup BP at full brake pressure" 14 "Maximum recup rear" 13 "Maximum recup front" 12 "Maximum torque rear" 11 "Maximum torque front" 10 "Maximum RPM Inverter" 9 "Maximum RPM controlled by MCU" 8 "Maximum power" 7 "Endurance Limiter maximum SoC" 6 "Endurance Limiter minimum SoC" 5 "Endurance Limiter enabled" 4 "Traction Control enabled" 3 "Engine Brake enabled" 2 "Torque Vectoring enabled" 1 "Recuperation enabled" 0 "Reset Flash" ;
VAL_ 1616 CCU_Config_ID_RX 15 "Voltage pump right" 14 "Voltage pump left" 13 "Laptrigger enabled (reboot)" 12 "Control eFuse Inverter right" 11 "Control eFuse Inverter left" 10 "Control eFuse Accumulator" 9 "Control eFuse CAN node" 8 "Torque pedal max way (mech lim)" 7 "Torque pedal full way (kickdown)" 6 "DRS mode" 5 "Fan Cooling manual speed" 4 "Fan Accu manual speed" 3 "Pump Inverter manual speed" 2 "Pump Motor manual speed" 1 "Cool mode" 0 "Reset Flash" ;
VAL_ 1557 MCU_Config_ID_RD 45 "Brake pessure RTD limit" 44 "Brake Pressure plausibility lim" 43 "Recup ENC full at position" 42 "Brake pedal lower mech lim" 41 "Torque pedal upper mech lim" 40 "Torque pedal kickdown start" 39 "Torque pedal lower mech lim" 38 "Torque pedal mechanical tol" 37 "Set total distance recorder (!)" 36 "Inverter calibration mode" 35 "Traction Control T_Rear" 34 "Traction Control T_Front" 33 "Taction Control Kp" 32 "MCU speed controller Kp" 31 "Torque graph end derivation" 30 "Torque graph start derivation" 29 "Torque Vectoring exponent" 28 "Recup Vectoring max neg shift R" 27 "Recup Vectoring max pos shift R" 26 "Recup Vectoring max neg shift F" 25 "Recup Vectoring max pos shift F" 24 "Torque Vectoring max neg shift R" 23 "Torque Vectoring max pos shift R" 22 "Torque Vectoring max neg shift F" 21 "Torque Vectoring max pos shift F" 20 "Engine Brake" 19 "Torque Vectoring 100% steerangle" 18 "Recup ENC weight" 17 "Recup BP weight" 16 "Maximum recuperation current" 15 "Recup BP at full brake pressure" 14 "Maximum recup rear" 13 "Maximum recup front" 12 "Maximum torque rear" 11 "Maximum torque front" 10 "Maximum RPM Inverter" 9 "Maximum RPM controlled by MCU" 8 "Maximum power" 7 "Endurance Limiter maximum SoC" 6 "Endurance Limiter minimum SoC" 5 "Endurance Limiter enabled" 4 "Traction Control enabled" 3 "Engine Brake enabled" 2 "Torque Vectoring enabled" 1 "Recuperation enabled" 0 "Reset Flash" ;
VAL_ 1541 CCU_Config_ID_RD 15 "Voltage pump right" 14 "Voltage pump left" 13 "Laptrigger enabled (reboot)" 12 "Control eFuse Inverter right" 11 "Control eFuse Inverter left" 10 "Control eFuse Accumulator" 9 "Control eFuse CAN node" 8 "Torque pedal max way (mech lim)" 7 "Torque pedal full way (kickdown)" 6 "DRS mode" 5 "Fan Cooling manual speed" 4 "Fan Accu manual speed" 3 "Pump Inverter manual speed" 2 "Pump Motor manual speed" 1 "Cool mode" 0 "Reset Flash" ;
